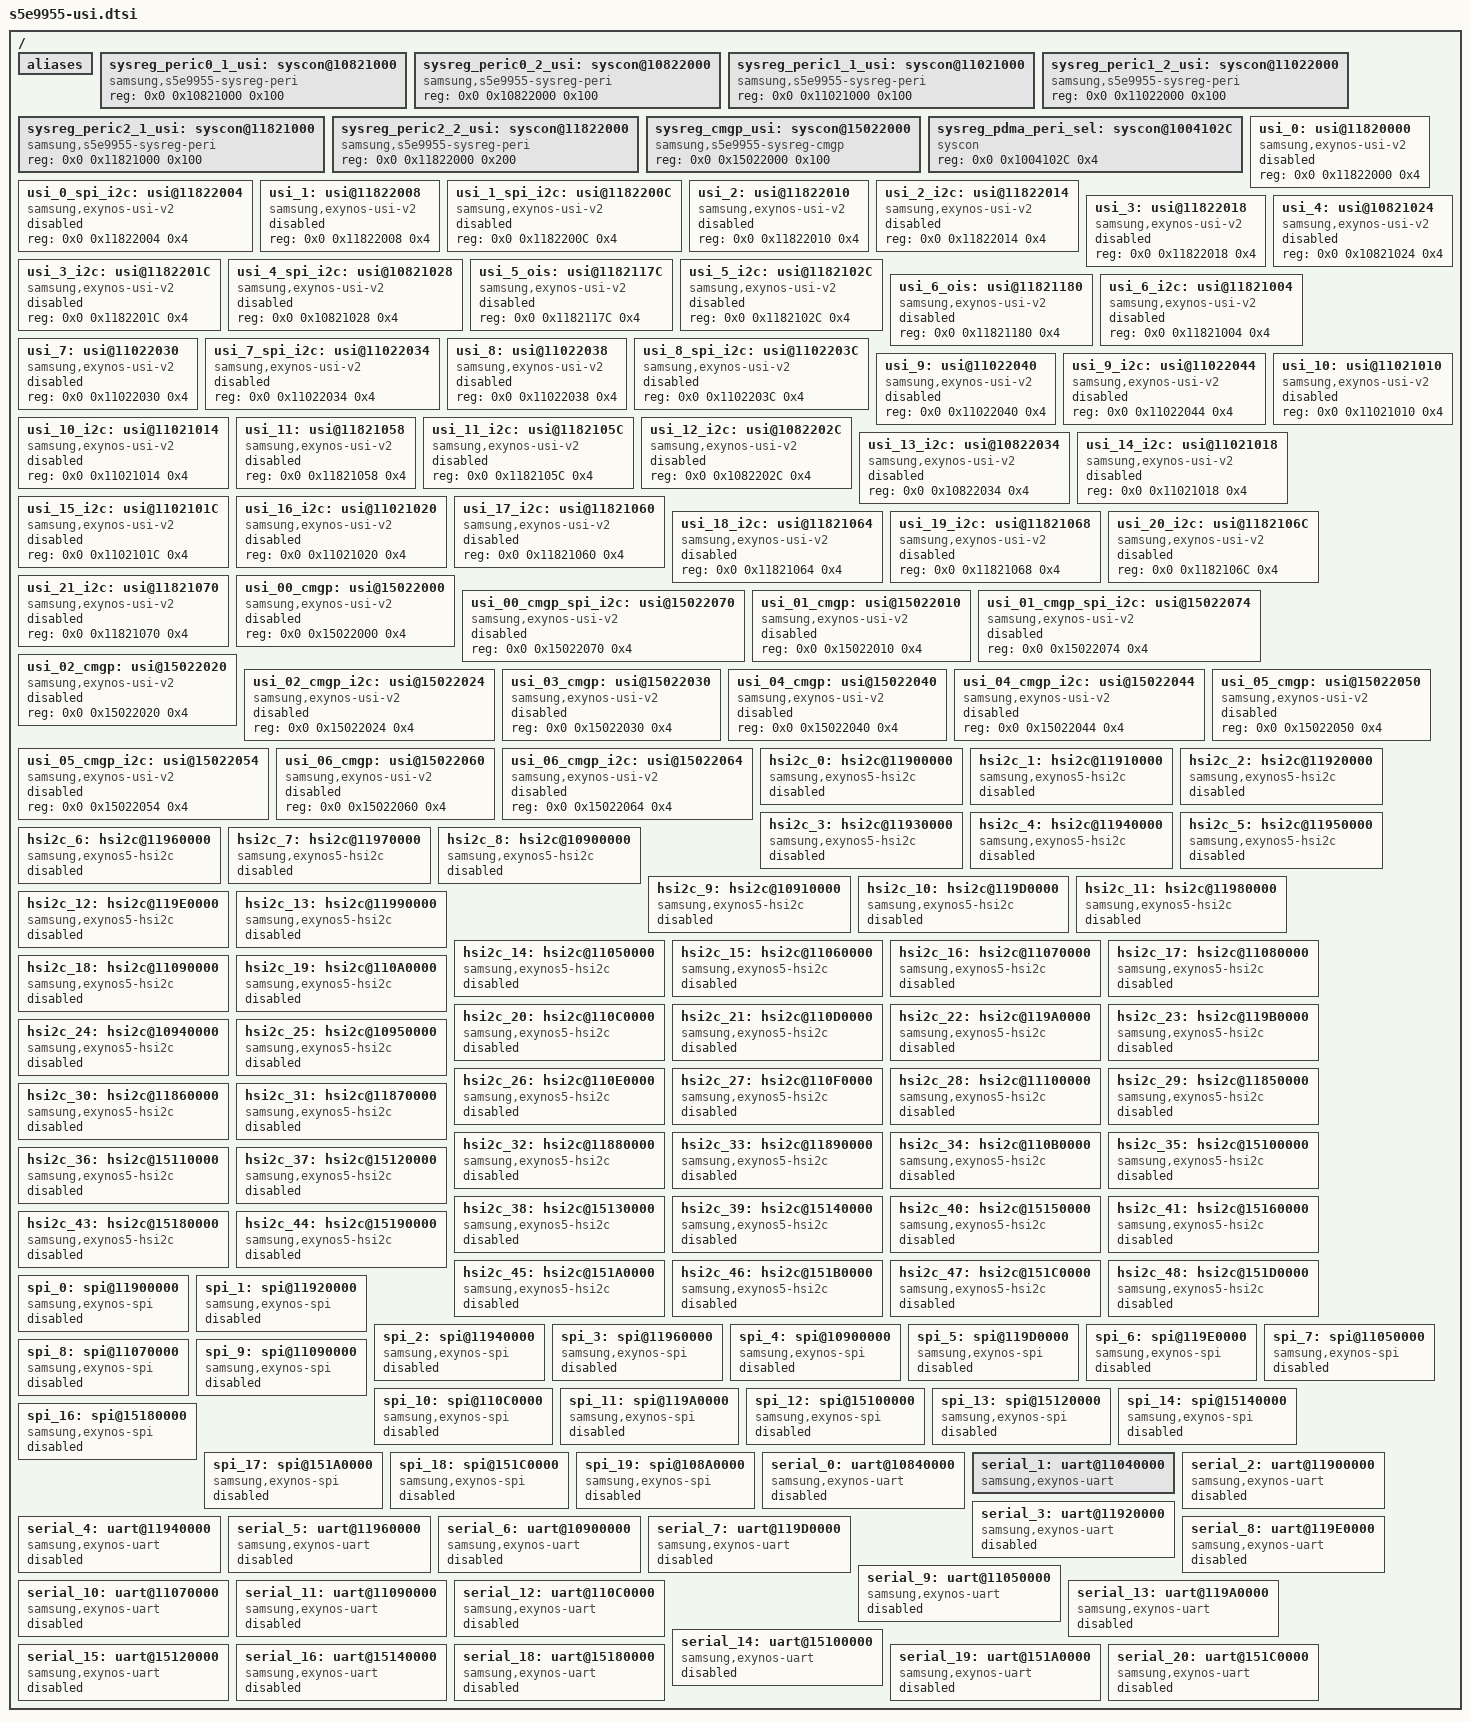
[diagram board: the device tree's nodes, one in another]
/*
 * Samsung's s5e9955 SoC USI device tree source
 *
 * Copyright (c) 2023 Samsung Electronics Co., Ltd.
 *		http://www.samsung.com
 *
 * Samsung's s5e9955 SoC USI channels are listed as device
 * tree nodes are listed in this file.
 *
 * This program is free software; you can redistribute it and/or modify
 * it under the terms of the GNU General Public License version 2 as
 * published by the Free Software Foundation.
*/

/ {
	aliases {
		usi00 = &usi_0;
		usi01 = &usi_0_spi_i2c;
		usi02 = &usi_1;
		usi03 = &usi_1_spi_i2c;
		usi04 = &usi_2;
		usi05 = &usi_2_i2c;
		usi06 = &usi_3;
		usi07 = &usi_3_i2c;
		usi08 = &usi_4;
		usi09 = &usi_4_spi_i2c;
		usi10 = &usi_5_ois;
		usi11 = &usi_5_i2c;
		usi12 = &usi_6_ois;
		usi13 = &usi_6_i2c;
		usi14 = &usi_7;
		usi15 = &usi_7_spi_i2c;
		usi16 = &usi_8;
		usi17 = &usi_8_spi_i2c;
		usi18 = &usi_9;
		usi19 = &usi_9_i2c;
		usi20 = &usi_10;
		usi21 = &usi_10_i2c;
		usi22 = &usi_11;
		usi23 = &usi_11_i2c;
		usi24 = &usi_12_i2c;
		usi25 = &usi_13_i2c;
		usi26 = &usi_14_i2c;
		usi27 = &usi_15_i2c;
		usi28 = &usi_16_i2c;
		usi29 = &usi_17_i2c;
		usi30 = &usi_18_i2c;
		usi31 = &usi_19_i2c;
		usi32 = &usi_20_i2c;
		usi33 = &usi_21_i2c;
		usi34 = &usi_00_cmgp;
		usi35 = &usi_00_cmgp_spi_i2c;
		usi36 = &usi_01_cmgp;
		usi37 = &usi_01_cmgp_spi_i2c;
		usi38 = &usi_02_cmgp;
		usi39 = &usi_02_cmgp_i2c;
		usi40 = &usi_03_cmgp;
		//usi41 = &usi_03_cmgp_i2c;
		usi42 = &usi_04_cmgp;
		usi43 = &usi_04_cmgp_i2c;
		usi44 = &usi_05_cmgp;
		usi45 = &usi_05_cmgp_i2c;
		usi46 = &usi_06_cmgp;
		usi47 = &usi_06_cmgp_i2c;
		i2c0 = &hsi2c_0;
		i2c1 = &hsi2c_1;
		i2c2 = &hsi2c_2;
		i2c3 = &hsi2c_3;
		i2c4 = &hsi2c_4;
		i2c5 = &hsi2c_5;
		i2c6 = &hsi2c_6;
		i2c7 = &hsi2c_7;
		i2c8 = &hsi2c_8;
		i2c9 = &hsi2c_9;
		i2c10 = &hsi2c_10;
		i2c11 = &hsi2c_11;
		i2c12 = &hsi2c_12;
		i2c13 = &hsi2c_13;
		i2c14 = &hsi2c_14;
		i2c15 = &hsi2c_15;
		i2c16 = &hsi2c_16;
		i2c17 = &hsi2c_17;
		i2c18 = &hsi2c_18;
		i2c19 = &hsi2c_19;
		i2c20 = &hsi2c_20;
		i2c21 = &hsi2c_21;
		i2c22 = &hsi2c_22;
		i2c23 = &hsi2c_23;
		i2c24 = &hsi2c_24;
		i2c25 = &hsi2c_25;
		i2c26 = &hsi2c_26;
		i2c27 = &hsi2c_27;
		i2c28 = &hsi2c_28;
		i2c29 = &hsi2c_29;
		i2c30 = &hsi2c_30;
		i2c31 = &hsi2c_31;
		i2c32 = &hsi2c_32;
		i2c33 = &hsi2c_33;
		i2c34 = &hsi2c_34;
		i2c35 = &hsi2c_35;
		i2c36 = &hsi2c_36;
		i2c37 = &hsi2c_37;
		i2c38 = &hsi2c_38;
		i2c39 = &hsi2c_39;
		i2c40 = &hsi2c_40;
		i2c41 = &hsi2c_41;
		//hsi2c42 = &hsi2c_42;
		i2c43 = &hsi2c_43;
		i2c44 = &hsi2c_44;
		i2c45 = &hsi2c_45;
		i2c46 = &hsi2c_46;
		i2c47 = &hsi2c_47;
		i2c48 = &hsi2c_48;

		// Exynos SoC mfd
		i2c50 = &esca_mfd_bus0;
		i2c51 = &esca_mfd_bus1;
		i2c52 = &esca_mfd_bus2;
		i2c53 = &esca_mfd_bus3;
		i2c54 = &esca_mfd_bus4;
		i2c55 = &esca_mfd_bus5;
		i2c56 = &esca_mfd_bus6;
		i2c57 = &esca_mfd_bus7;
		i2c58 = &esca_mfd_bus8;

		spi0 = &spi_0;
		spi1 = &spi_1;
		spi2 = &spi_2;
		spi3 = &spi_3;
		spi4 = &spi_4;
		spi5 = &spi_5;
		spi6 = &spi_6;
		spi7 = &spi_7;
		spi8 = &spi_8;
		spi9 = &spi_9;
		spi10 = &spi_10;
		spi11 = &spi_11;
		spi12 = &spi_12;
		spi13 = &spi_13;
		spi14 = &spi_14;
		//spi15 = &spi_15;
		spi16 = &spi_16;
		spi17 = &spi_17;
		spi18 = &spi_18;
		spi19 = &spi_19;
		uart0 = &serial_0;
		uart1 = &serial_1;
		uart2 = &serial_2;
		uart3 = &serial_3;
		uart4 = &serial_4;
		uart5 = &serial_5;
		uart6 = &serial_6;
		uart7 = &serial_7;
		uart8 = &serial_8;
		uart9 = &serial_9;
		uart10 = &serial_10;
		uart11 = &serial_11;
		uart12 = &serial_12;
		uart13 = &serial_13;
		uart14 = &serial_14;
		uart15 = &serial_15;
		uart16 = &serial_16;
		//uart17 = &serial_17;
		uart18 = &serial_18;
		uart19 = &serial_19;
		uart20 = &serial_20;
	};

	/* USI_SW_CONF for PERIC0-1 USI*/
	sysreg_peric0_1_usi: syscon@10821000 {
		compatible = "samsung,s5e9955-sysreg-peri", "syscon";
		reg = <0x0 0x10821000 0x100>;
	};

	/* USI_SW_CONF for PERIC0-2 USI*/
	sysreg_peric0_2_usi: syscon@10822000 {
		compatible = "samsung,s5e9955-sysreg-peri", "syscon";
		reg = <0x0 0x10822000 0x100>;
	};

	/* USI_SW_CONF for PERIC1-1 USI*/
	sysreg_peric1_1_usi: syscon@11021000 {
		compatible = "samsung,s5e9955-sysreg-peri", "syscon";
		reg = <0x0 0x11021000 0x100>;
	};

	/* USI_SW_CONF for PERIC1-2 USI*/
	sysreg_peric1_2_usi: syscon@11022000 {
		compatible = "samsung,s5e9955-sysreg-peri", "syscon";
		reg = <0x0 0x11022000 0x100>;
	};

	/* USI_SW_CONF for PERIC2-1 USI*/
	sysreg_peric2_1_usi: syscon@11821000 {
		compatible = "samsung,s5e9955-sysreg-peri", "syscon";
		reg = <0x0 0x11821000 0x100>;
	};

	/* USI_SW_CONF for PERIC2-2 USI*/
	sysreg_peric2_2_usi: syscon@11822000 {
		compatible = "samsung,s5e9955-sysreg-peri", "syscon";
		reg = <0x0 0x11822000 0x200>;
	};

	/* USI_SW_CONF for CMGP USI*/
	sysreg_cmgp_usi: syscon@15022000 {
		compatible = "samsung,s5e9955-sysreg-cmgp", "syscon";
		reg = <0x0 0x15022000 0x100>;
	};

	/* SYSREG PDMA_PERI_SEL */
	/* Refer to UM System register PDMA_PERI_SEL */
	sysreg_pdma_peri_sel: syscon@1004102C {
		compatible = "syscon";
		reg = <0x0 0x1004102C 0x4>;
	};

	/* USI_0 */
	usi_0: usi@11820000 {
		compatible = "samsung,exynos-usi-v2";
		reg = <0x0 0x11822000 0x4>;
		/*	usi_v2_mode = "i2c" or "spi" or "uart"	*/
		status = "disabled";
	};

	/* USI_0_SPI_I2C */
	usi_0_spi_i2c: usi@11822004 {
		compatible = "samsung,exynos-usi-v2";
		reg = <0x0 0x11822004 0x4>;
		/*	usi_v2_mode = "i2c" or "spi" or "uart"	*/
		status = "disabled";
	};

	/* USI_1 */
	usi_1: usi@11822008 {
		compatible = "samsung,exynos-usi-v2";
		reg = <0x0 0x11822008 0x4>;
		/*	usi_v2_mode = "i2c" or "spi" or "uart"	*/
		status = "disabled";
	};

	/* USI_1_SPI_I2C */
	usi_1_spi_i2c: usi@1182200C {
		compatible = "samsung,exynos-usi-v2";
		reg = <0x0 0x1182200C 0x4>;
		/*	usi_v2_mode = "i2c" or "spi" or "uart"	*/
		status = "disabled";
	};

	/* USI_2 */
	usi_2: usi@11822010 {
		compatible = "samsung,exynos-usi-v2";
		reg = <0x0 0x11822010 0x4>;
		/*	usi_v2_mode = "i2c" or "spi" or "uart"	*/
		status = "disabled";
	};

	/* USI_2_I2C */
	usi_2_i2c: usi@11822014 {
		compatible = "samsung,exynos-usi-v2";
		reg = <0x0 0x11822014 0x4>;
		/*	usi_v2_mode = "i2c" or "spi" or "uart"	*/
		status = "disabled";
	};

	/* USI_3 */
	usi_3: usi@11822018 {
		compatible = "samsung,exynos-usi-v2";
		reg = <0x0 0x11822018 0x4>;
		/*	usi_v2_mode = "i2c" or "spi" or "uart"	*/
		status = "disabled";
	};

	/* USI_3_I2C */
	usi_3_i2c: usi@1182201C {
		compatible = "samsung,exynos-usi-v2";
		reg = <0x0 0x1182201C 0x4>;
		/*	usi_v2_mode = "i2c" or "spi" or "uart"	*/
		status = "disabled";
	};

	/* USI_4 */
	usi_4: usi@10821024 {
		compatible = "samsung,exynos-usi-v2";
		reg = <0x0 0x10821024 0x4>;
		/*	usi_v2_mode = "i2c" or "spi" or "uart"	*/
		status = "disabled";
	};

	/* USI_4_I2C */
	usi_4_spi_i2c: usi@10821028 {
		compatible = "samsung,exynos-usi-v2";
		reg = <0x0 0x10821028 0x4>;
		/*	usi_v2_mode = "i2c" or "spi" or "uart"	*/
		status = "disabled";
	};

	/* USI_5_OIS */
	usi_5_ois: usi@1182117C {
		compatible = "samsung,exynos-usi-v2";
		reg = <0x0 0x1182117C 0x4>;
		/*	usi_v2_mode = "i2c" or "spi" or "uart"	*/
		status = "disabled";
	};

	/* USI_5_I2C */
	usi_5_i2c: usi@1182102C {
		compatible = "samsung,exynos-usi-v2";
		reg = <0x0 0x1182102C 0x4>;
		/*	usi_v2_mode = "i2c" or "spi" or "uart"	*/
		status = "disabled";
	};

	/* USI_6_OIS */
	usi_6_ois: usi@11821180 {
		compatible = "samsung,exynos-usi-v2";
		reg = <0x0 0x11821180 0x4>;
		/*	usi_v2_mode = "i2c" or "spi" or "uart"	*/
		status = "disabled";
	};

	/* USI_6_I2C */
	usi_6_i2c: usi@11821004 {
		compatible = "samsung,exynos-usi-v2";
		reg = <0x0 0x11821004 0x4>;
		/*	usi_v2_mode = "i2c" or "spi" or "uart"	*/
		status = "disabled";
	};

	/* USI_7 */
	usi_7: usi@11022030 {
		compatible = "samsung,exynos-usi-v2";
		reg = <0x0 0x11022030 0x4>;
		/*	usi_v2_mode = "i2c" or "spi" or "uart"	*/
		status = "disabled";
	};

	/* USI_7_SPI_I2C */
	usi_7_spi_i2c: usi@11022034 {
		compatible = "samsung,exynos-usi-v2";
		reg = <0x0 0x11022034 0x4>;
		/*	usi_v2_mode = "i2c" or "spi" or "uart"	*/
		status = "disabled";
	};

	/* USI_8 */
	usi_8: usi@11022038 {
		compatible = "samsung,exynos-usi-v2";
		reg = <0x0 0x11022038 0x4>;
		/*	usi_v2_mode = "i2c" or "spi" or "uart"	*/
		status = "disabled";
	};

	/* USI_8_SPI_I2C */
	usi_8_spi_i2c: usi@1102203C {
		compatible = "samsung,exynos-usi-v2";
		reg = <0x0 0x1102203C 0x4>;
		/*	usi_v2_mode = "i2c" or "spi" or "uart"	*/
		status = "disabled";
	};

	/* USI_9 */
	usi_9: usi@11022040 {
		compatible = "samsung,exynos-usi-v2";
		reg = <0x0 0x11022040 0x4>;
		/*	usi_v2_mode = "i2c" or "spi" or "uart"	*/
		status = "disabled";
	};

	/* USI_9_I2C */
	usi_9_i2c: usi@11022044 {
		compatible = "samsung,exynos-usi-v2";
		reg = <0x0 0x11022044 0x4>;
		/*	usi_v2_mode = "i2c" or "spi" or "uart"	*/
		status = "disabled";
	};

	/* USI_10 */
	usi_10: usi@11021010 {
		compatible = "samsung,exynos-usi-v2";
		reg = <0x0 0x11021010 0x4>;
		/*	usi_v2_mode = "i2c" or "spi" or "uart"	*/
		status = "disabled";
	};

	/* USI_10_I2C */
	usi_10_i2c: usi@11021014 {
		compatible = "samsung,exynos-usi-v2";
		reg = <0x0 0x11021014 0x4>;
		/*	usi_v2_mode = "i2c" or "spi" or "uart"	*/
		status = "disabled";
	};

	/* USI_11 */
	usi_11: usi@11821058 {
		compatible = "samsung,exynos-usi-v2";
		reg = <0x0 0x11821058 0x4>;
		/*	usi_v2_mode = "i2c" or "spi" or "uart"	*/
		status = "disabled";
	};

	/* USI_11_I2C */
	usi_11_i2c: usi@1182105C {
		compatible = "samsung,exynos-usi-v2";
		reg = <0x0 0x1182105C 0x4>;
		/*	usi_v2_mode = "i2c" or "spi" or "uart"	*/
		status = "disabled";
	};

	/* USI_12_I2C */
	usi_12_i2c: usi@1082202C {
		compatible = "samsung,exynos-usi-v2";
		reg = <0x0 0x1082202C 0x4>;
		/*	usi_v2_mode = "i2c" or "spi" or "uart"	*/
		status = "disabled";
	};

	/* USI_13_I2C */
	usi_13_i2c: usi@10822034 {
		compatible = "samsung,exynos-usi-v2";
		reg = <0x0 0x10822034 0x4>;
		/*	usi_v2_mode = "i2c" or "spi" or "uart"	*/
		status = "disabled";
	};

	/* USI_14_I2C */
	usi_14_i2c: usi@11021018 {
		compatible = "samsung,exynos-usi-v2";
		reg = <0x0 0x11021018 0x4>;
		/*	usi_v2_mode = "i2c" or "spi" or "uart"	*/
		status = "disabled";
	};

	/* USI_15_I2C */
	usi_15_i2c: usi@1102101C {
		compatible = "samsung,exynos-usi-v2";
		reg = <0x0 0x1102101C 0x4>;
		/*	usi_v2_mode = "i2c" or "spi" or "uart"	*/
		status = "disabled";
	};

	/* USI_16_I2C */
	usi_16_i2c: usi@11021020 {
		compatible = "samsung,exynos-usi-v2";
		reg = <0x0 0x11021020 0x4>;
		/*	usi_v2_mode = "i2c" or "spi" or "uart"	*/
		status = "disabled";
	};

	/* USI_17_I2C */
	usi_17_i2c: usi@11821060 {
		compatible = "samsung,exynos-usi-v2";
		reg = <0x0 0x11821060 0x4>;
		/*	usi_v2_mode = "i2c" or "spi" or "uart"	*/
		status = "disabled";
	};

	/* USI_18_I2C */
	usi_18_i2c: usi@11821064 {
		compatible = "samsung,exynos-usi-v2";
		reg = <0x0 0x11821064 0x4>;
		/*	usi_v2_mode = "i2c" or "spi" or "uart"	*/
		status = "disabled";
	};

	/* USI_19_I2C */
	usi_19_i2c: usi@11821068 {
		compatible = "samsung,exynos-usi-v2";
		reg = <0x0 0x11821068 0x4>;
		/*	usi_v2_mode = "i2c" or "spi" or "uart"	*/
		status = "disabled";
	};

	/* USI_20_I2C */
	usi_20_i2c: usi@1182106C {
		compatible = "samsung,exynos-usi-v2";
		reg = <0x0 0x1182106C 0x4>;
		/*	usi_v2_mode = "i2c" or "spi" or "uart"	*/
		status = "disabled";
	};

	/* USI_21_I2C */
	usi_21_i2c: usi@11821070 {
		compatible = "samsung,exynos-usi-v2";
		reg = <0x0 0x11821070 0x4>;
		/*	usi_v2_mode = "i2c" or "spi" or "uart"	*/
		status = "disabled";
	};

	/* USI_CMGP0_USI */
	usi_00_cmgp: usi@15022000 {
		compatible = "samsung,exynos-usi-v2";
		reg = <0x0 0x15022000 0x4>;
		/*	usi_v2_mode = "i2c" or "spi" or "uart"	*/
		status = "disabled";
	};

	/* USI_CMGP0_SPI_I2C */
	usi_00_cmgp_spi_i2c: usi@15022070 {
		compatible = "samsung,exynos-usi-v2";
		reg = <0x0 0x15022070 0x4>;
		/*	usi_v2_mode = "i2c" or "spi" or "uart"	*/
		status = "disabled";
	};

	/* USI_CMGP1_USI */
	usi_01_cmgp: usi@15022010 {
		compatible = "samsung,exynos-usi-v2";
		reg = <0x0 0x15022010 0x4>;
		/*	usi_v2_mode = "i2c" or "spi" or "uart"	*/
		status = "disabled";
	};

	/* USI_CMGP1_SPI_I2C */
	usi_01_cmgp_spi_i2c: usi@15022074 {
		compatible = "samsung,exynos-usi-v2";
		reg = <0x0 0x15022074 0x4>;
		/*	usi_v2_mode = "i2c" or "spi" or "uart"	*/
		status = "disabled";
	};

	/* USI_CMGP2_USI */
	usi_02_cmgp: usi@15022020 {
		compatible = "samsung,exynos-usi-v2";
		reg = <0x0 0x15022020 0x4>;
		/*	usi_v2_mode = "i2c" or "spi" or "uart"	*/
		status = "disabled";
	};

	/* USI_CMGP2_I2C */
	usi_02_cmgp_i2c: usi@15022024 {
		compatible = "samsung,exynos-usi-v2";
		reg = <0x0 0x15022024 0x4>;
		/*	usi_v2_mode = "i2c" or "spi" or "uart"	*/
		status = "disabled";
	};

	/* USI_CMGP3_USI */
	usi_03_cmgp: usi@15022030 {
		compatible = "samsung,exynos-usi-v2";
		reg = <0x0 0x15022030 0x4>;
		/*	usi_v2_mode = "i2c" or "spi" or "uart"	*/
		status = "disabled";
	};

	/* USI_CMGP3_I2C */
/*
	usi_03_cmgp_i2c: usi@15022034 {
		compatible = "samsung,exynos-usi-v2";
		reg = <0x0 0x15022034 0x4>;
		//	usi_v2_mode = "i2c" or "spi" or "uart"
		status = "disabled";
	};
*/
	/* USI_CMGP4_USI */
	usi_04_cmgp: usi@15022040 {
		compatible = "samsung,exynos-usi-v2";
		reg = <0x0 0x15022040 0x4>;
		/*	usi_v2_mode = "i2c" or "spi" or "uart"	*/
		status = "disabled";
	};

	/* USI_CMGP4_I2C */
	usi_04_cmgp_i2c: usi@15022044 {
		compatible = "samsung,exynos-usi-v2";
		reg = <0x0 0x15022044 0x4>;
		/*	usi_v2_mode = "i2c" or "spi" or "uart"	*/
		status = "disabled";
	};

	/* USI_CMGP5_USI */
	usi_05_cmgp: usi@15022050 {
		compatible = "samsung,exynos-usi-v2";
		reg = <0x0 0x15022050 0x4>;
		/*	usi_v2_mode = "i2c" or "spi" or "uart"	*/
		status = "disabled";
	};

	/* USI_CMGP5_I2C */
	usi_05_cmgp_i2c: usi@15022054 {
		compatible = "samsung,exynos-usi-v2";
		reg = <0x0 0x15022054 0x4>;
		/*	usi_v2_mode = "i2c" or "spi" or "uart"	*/
		status = "disabled";
	};

	/* USI_CMGP6_USI */
	usi_06_cmgp: usi@15022060 {
		compatible = "samsung,exynos-usi-v2";
		reg = <0x0 0x15022060 0x4>;
		/*	usi_v2_mode = "i2c" or "spi" or "uart"	*/
		status = "disabled";
	};

	/* USI_CMGP6_I2C */
	usi_06_cmgp_i2c: usi@15022064 {
		compatible = "samsung,exynos-usi-v2";
		reg = <0x0 0x15022064 0x4>;
		/*	usi_v2_mode = "i2c" or "spi" or "uart"	*/
		status = "disabled";
	};

	/* USI00_USI */
	hsi2c_0: hsi2c@11900000 {
		compatible = "samsung,exynos5-hsi2c";
		samsung,check-transdone-int;
		default-clk = <200000000>;
		samsung,scl-clk-stretching;
		samsung,reset-before-trans;
		samsung,i2c-bus-clear = <1>;
		#address-cells = <1>;
		#size-cells = <0>;
		interrupts = <GIC_SPI INTREQ__USI00_USI IRQ_TYPE_LEVEL_HIGH>;
		samsung,usi-phandle = <&sysreg_peric2_2_usi>;
		samsung,usi-offset = <0x00>;
		reg = <0x0 0x11900000 0x1000>;
		pinctrl-names = "default", "bus_io";
		pinctrl-0 = <&hsi2c0_bus>;
		pinctrl-1 = <&hsi2c0_bus_io>;
		clocks = <&clock DOUT_DIV_CLK_PERIC2_USI00>, <&clock GATE_PERIC2_CMU_PERIC2_QCH>;
		clock-names = "ipclk_hsi2c", "gate_hsi2c_clk";
		gpio_scl= <&gpp0 0 0x1>;
		gpio_sda= <&gpp0 1 0x1>;
		status = "disabled";
	};

	/* USI00_I2C */
	hsi2c_1: hsi2c@11910000 {
		compatible = "samsung,exynos5-hsi2c";
		samsung,check-transdone-int;
		default-clk = <200000000>;
		samsung,scl-clk-stretching;
		samsung,reset-before-trans;
		samsung,i2c-bus-clear = <1>;
		#address-cells = <1>;
		#size-cells = <0>;
		interrupts = <GIC_SPI INTREQ__USI00_SPI_I2C IRQ_TYPE_LEVEL_HIGH>;
		samsung,usi-phandle = <&sysreg_peric2_2_usi>;
		samsung,usi-offset = <0x04>;
		reg = <0x0 0x11910000 0x1000>;
		pinctrl-names = "default", "bus_io";
		pinctrl-0 = <&hsi2c1_bus>;
		pinctrl-1 = <&hsi2c1_bus_io>;
		clocks = <&clock DOUT_DIV_CLK_PERIC2_USI00_SPI_I2C>, <&clock GATE_PERIC2_CMU_PERIC2_QCH>;
		clock-names = "ipclk_hsi2c", "gate_hsi2c_clk";
		gpio_scl= <&gpp0 2 0x1>;
		gpio_sda= <&gpp0 3 0x1>;
		status = "disabled";
	};

	/* USI01_USI */
	hsi2c_2: hsi2c@11920000 {
		compatible = "samsung,exynos5-hsi2c";
		samsung,check-transdone-int;
		default-clk = <200000000>;
		samsung,scl-clk-stretching;
		samsung,reset-before-trans;
		samsung,i2c-bus-clear = <1>;
		#address-cells = <1>;
		#size-cells = <0>;
		interrupts = <GIC_SPI INTREQ__USI01_USI IRQ_TYPE_LEVEL_HIGH>;
		samsung,usi-phandle = <&sysreg_peric2_2_usi>;
		samsung,usi-offset = <0x08>;
		reg = <0x0 0x11920000 0x1000>;
		pinctrl-names = "default", "bus_io";
		pinctrl-0 = <&hsi2c2_bus>;
		pinctrl-1 = <&hsi2c2_bus_io>;
		clocks = <&clock DOUT_DIV_CLK_PERIC2_USI01>, <&clock GATE_PERIC2_CMU_PERIC2_QCH>;
		clock-names = "ipclk_hsi2c", "gate_hsi2c_clk";
		gpio_scl= <&gpp1 0 0x1>;
		gpio_sda= <&gpp1 1 0x1>;
		status = "disabled";
	};

	/* USI01_I2C */
	hsi2c_3: hsi2c@11930000 {
		compatible = "samsung,exynos5-hsi2c";
		samsung,check-transdone-int;
		default-clk = <200000000>;
		samsung,scl-clk-stretching;
		samsung,reset-before-trans;
		samsung,i2c-bus-clear = <1>;
		#address-cells = <1>;
		#size-cells = <0>;
		interrupts = <GIC_SPI INTREQ__USI01_SPI_I2C IRQ_TYPE_LEVEL_HIGH>;
		samsung,usi-phandle = <&sysreg_peric2_2_usi>;
		samsung,usi-offset = <0x0C>;
		reg = <0x0 0x11930000 0x1000>;
		pinctrl-names = "default", "bus_io";
		pinctrl-0 = <&hsi2c3_bus>;
		pinctrl-1 = <&hsi2c3_bus_io>;
		clocks = <&clock DOUT_DIV_CLK_PERIC2_USI01_SPI_I2C>, <&clock GATE_PERIC2_CMU_PERIC2_QCH>;
		clock-names = "ipclk_hsi2c", "gate_hsi2c_clk";
		gpio_scl= <&gpp1 2 0x1>;
		gpio_sda= <&gpp1 3 0x1>;
		status = "disabled";
	};

	/* USI02_USI */
	hsi2c_4: hsi2c@11940000 {
		compatible = "samsung,exynos5-hsi2c";
		samsung,check-transdone-int;
		default-clk = <200000000>;
		samsung,scl-clk-stretching;
		samsung,reset-before-trans;
		samsung,i2c-bus-clear = <1>;
		#address-cells = <1>;
		#size-cells = <0>;
		interrupts = <GIC_SPI INTREQ__USI02_USI IRQ_TYPE_LEVEL_HIGH>;
		samsung,usi-phandle = <&sysreg_peric2_2_usi>;
		samsung,usi-offset = <0x10>;
		reg = <0x0 0x11940000 0x1000>;
		pinctrl-names = "default", "bus_io";
		pinctrl-0 = <&hsi2c4_bus>;
		pinctrl-1 = <&hsi2c4_bus_io>;
		clocks = <&clock DOUT_DIV_CLK_PERIC2_USI02>, <&clock GATE_PERIC2_CMU_PERIC2_QCH>;
		clock-names = "ipclk_hsi2c", "gate_hsi2c_clk";
		gpio_scl= <&gpp2 0 0x1>;
		gpio_sda= <&gpp2 1 0x1>;
		status = "disabled";
	};

	/* USI02_I2C */
	hsi2c_5: hsi2c@11950000 {
		compatible = "samsung,exynos5-hsi2c";
		samsung,check-transdone-int;
		default-clk = <200000000>;
		samsung,scl-clk-stretching;
		samsung,reset-before-trans;
		samsung,i2c-bus-clear = <1>;
		#address-cells = <1>;
		#size-cells = <0>;
		interrupts = <GIC_SPI INTREQ__USI02_I2C IRQ_TYPE_LEVEL_HIGH>;
		samsung,usi-phandle = <&sysreg_peric2_2_usi>;
		samsung,usi-offset = <0x14>;
		reg = <0x0 0x11950000 0x1000>;
		pinctrl-names = "default", "bus_io";
		pinctrl-0 = <&hsi2c5_bus>;
		pinctrl-1 = <&hsi2c5_bus_io>;
		clocks = <&clock DOUT_DIV_CLK_PERIC2_I2C>, <&clock GATE_PERIC2_CMU_PERIC2_QCH>;
		clock-names = "ipclk_hsi2c", "gate_hsi2c_clk";
		gpio_scl= <&gpp2 2 0x1>;
		gpio_sda= <&gpp2 3 0x1>;
		status = "disabled";
	};

	/* USI03_USI */
	hsi2c_6: hsi2c@11960000 {
		compatible = "samsung,exynos5-hsi2c";
		samsung,check-transdone-int;
		default-clk = <200000000>;
		samsung,scl-clk-stretching;
		samsung,reset-before-trans;
		samsung,i2c-bus-clear = <1>;
		#address-cells = <1>;
		#size-cells = <0>;
		interrupts = <GIC_SPI INTREQ__USI03_USI IRQ_TYPE_LEVEL_HIGH>;
		samsung,usi-phandle = <&sysreg_peric2_2_usi>;
		samsung,usi-offset = <0x18>;
		reg = <0x0 0x11960000 0x1000>;
		pinctrl-names = "default", "bus_io";
		pinctrl-0 = <&hsi2c6_bus>;
		pinctrl-1 = <&hsi2c6_bus_io>;
		clocks = <&clock DOUT_DIV_CLK_PERIC2_USI03>, <&clock GATE_PERIC2_CMU_PERIC2_QCH>;
		clock-names = "ipclk_hsi2c", "gate_hsi2c_clk";
		gpio_scl= <&gpp3 0 0x1>;
		gpio_sda= <&gpp3 1 0x1>;
		status = "disabled";
	};

	/* USI03_I2C */
	hsi2c_7: hsi2c@11970000 {
		compatible = "samsung,exynos5-hsi2c";
		samsung,check-transdone-int;
		default-clk = <200000000>;
		samsung,scl-clk-stretching;
		samsung,reset-before-trans;
		samsung,i2c-bus-clear = <1>;
		#address-cells = <1>;
		#size-cells = <0>;
		interrupts = <GIC_SPI INTREQ__USI03_I2C IRQ_TYPE_LEVEL_HIGH>;
		samsung,usi-phandle = <&sysreg_peric2_2_usi>;
		samsung,usi-offset = <0x1C>;
		reg = <0x0 0x11970000 0x1000>;
		pinctrl-names = "default", "bus_io";
		pinctrl-0 = <&hsi2c7_bus>;
		pinctrl-1 = <&hsi2c7_bus_io>;
		clocks = <&clock DOUT_DIV_CLK_PERIC2_I2C>, <&clock GATE_PERIC2_CMU_PERIC2_QCH>;
		clock-names = "ipclk_hsi2c", "gate_hsi2c_clk";
		gpio_scl= <&gpp3 2 0x1>;
		gpio_sda= <&gpp3 3 0x1>;
		status = "disabled";
	};

	/* USI04_USI */
	hsi2c_8: hsi2c@10900000 {
		compatible = "samsung,exynos5-hsi2c";
		samsung,check-transdone-int;
		default-clk = <200000000>;
		samsung,scl-clk-stretching;
		samsung,reset-before-trans;
		samsung,i2c-bus-clear = <1>;
		#address-cells = <1>;
		#size-cells = <0>;
		interrupts = <GIC_SPI INTREQ__USI04_USI IRQ_TYPE_LEVEL_HIGH>;
		samsung,usi-phandle = <&sysreg_peric0_1_usi>;
		samsung,usi-offset = <0x24>;
		reg = <0x0 0x10900000 0x1000>;
		pinctrl-names = "default", "bus_io";
		pinctrl-0 = <&hsi2c8_bus>;
		pinctrl-1 = <&hsi2c8_bus_io>;
		clocks = <&clock DOUT_DIV_CLK_PERIC0_USI04>, <&clock GATE_PERIC0_CMU_PERIC0_QCH>;
		clock-names = "ipclk_hsi2c", "gate_hsi2c_clk";
		gpio_scl= <&gpp4 0 0x1>;
		gpio_sda= <&gpp4 1 0x1>;
		status = "disabled";
	};

	/* USI04_I2C */
	hsi2c_9: hsi2c@10910000 {
		compatible = "samsung,exynos5-hsi2c";
		samsung,check-transdone-int;
		default-clk = <200000000>;
		samsung,scl-clk-stretching;
		samsung,reset-before-trans;
		samsung,i2c-bus-clear = <1>;
		#address-cells = <1>;
		#size-cells = <0>;
		interrupts = <GIC_SPI INTREQ__USI04_I2C IRQ_TYPE_LEVEL_HIGH>;
		samsung,usi-phandle = <&sysreg_peric0_1_usi>;
		samsung,usi-offset = <0x28>;
		reg = <0x0 0x10910000 0x1000>;
		pinctrl-names = "default", "bus_io";
		pinctrl-0 = <&hsi2c9_bus>;
		pinctrl-1 = <&hsi2c9_bus_io>;
		clocks = <&clock DOUT_DIV_CLK_PERIC0_I2C>, <&clock GATE_PERIC0_CMU_PERIC0_QCH>;
		clock-names = "ipclk_hsi2c", "gate_hsi2c_clk";
		gpio_scl= <&gpp4 2 0x1>;
		gpio_sda= <&gpp4 3 0x1>;
		status = "disabled";
	};

	/* USI05_USI_OIS */
	hsi2c_10: hsi2c@119D0000 {
		compatible = "samsung,exynos5-hsi2c";
		samsung,check-transdone-int;
		default-clk = <200000000>;
		samsung,scl-clk-stretching;
		samsung,reset-before-trans;
		samsung,i2c-bus-clear = <1>;
		#address-cells = <1>;
		#size-cells = <0>;
		interrupts = <GIC_SPI INTREQ__USI05_USI_OIS IRQ_TYPE_LEVEL_HIGH>;
		samsung,usi-phandle = <&sysreg_peric2_1_usi>;
		samsung,usi-offset = <0x17C>;
		reg = <0x0 0x119D0000 0x1000>;
		pinctrl-names = "default", "bus_io";
		pinctrl-0 = <&hsi2c10_bus>;
		pinctrl-1 = <&hsi2c10_bus_io>;
		clocks = <&clock DOUT_DIV_CLK_PERIC2_USI05>, <&clock GATE_PERIC2_CMU_PERIC2_QCH>;
		clock-names = "ipclk_hsi2c", "gate_hsi2c_clk";
		gpio_scl= <&gpp5 0 0x1>;
		gpio_sda= <&gpp5 1 0x1>;
		status = "disabled";
	};

	/* USI05_I2C */
	hsi2c_11: hsi2c@11980000 {
		compatible = "samsung,exynos5-hsi2c";
		samsung,check-transdone-int;
		default-clk = <200000000>;
		samsung,scl-clk-stretching;
		samsung,reset-before-trans;
		samsung,i2c-bus-clear = <1>;
		#address-cells = <1>;
		#size-cells = <0>;
		interrupts = <GIC_SPI INTREQ__USI05_I2C IRQ_TYPE_LEVEL_HIGH>;
		samsung,usi-phandle = <&sysreg_peric2_1_usi>;
		samsung,usi-offset = <0x2C>;
		reg = <0x0 0x11980000 0x1000>;
		pinctrl-names = "default", "bus_io";
		pinctrl-0 = <&hsi2c11_bus>;
		pinctrl-1 = <&hsi2c11_bus_io>;
		clocks = <&clock DOUT_DIV_CLK_PERIC2_I2C>, <&clock GATE_PERIC2_CMU_PERIC2_QCH>;
		clock-names = "ipclk_hsi2c", "gate_hsi2c_clk";
		gpio_scl= <&gpp5 2 0x1>;
		gpio_sda= <&gpp5 3 0x1>;
		status = "disabled";
	};

	/* USI06_USI_OIS */
	hsi2c_12: hsi2c@119E0000 {
		compatible = "samsung,exynos5-hsi2c";
		samsung,check-transdone-int;
		default-clk = <200000000>;
		samsung,scl-clk-stretching;
		samsung,reset-before-trans;
		samsung,i2c-bus-clear = <1>;
		#address-cells = <1>;
		#size-cells = <0>;
		interrupts = <GIC_SPI INTREQ__USI06_USI_OIS IRQ_TYPE_LEVEL_HIGH>;
		samsung,usi-phandle = <&sysreg_peric2_1_usi>;
		samsung,usi-offset = <0x180>;
		reg = <0x0 0x119E0000 0x1000>;
		pinctrl-names = "default", "bus_io";
		pinctrl-0 = <&hsi2c12_bus>;
		pinctrl-1 = <&hsi2c12_bus_io>;
		clocks = <&clock DOUT_DIV_CLK_PERIC2_USI06>, <&clock GATE_PERIC2_CMU_PERIC2_QCH>;
		clock-names = "ipclk_hsi2c", "gate_hsi2c_clk";
		gpio_scl= <&gpp6 0 0x1>;
		gpio_sda= <&gpp6 1 0x1>;
		status = "disabled";
	};

	/* USI06_I2C */
	hsi2c_13: hsi2c@11990000 {
		compatible = "samsung,exynos5-hsi2c";
		samsung,check-transdone-int;
		default-clk = <200000000>;
		samsung,scl-clk-stretching;
		samsung,reset-before-trans;
		samsung,i2c-bus-clear = <1>;
		#address-cells = <1>;
		#size-cells = <0>;
		interrupts = <GIC_SPI INTREQ__USI06_I2C IRQ_TYPE_LEVEL_HIGH>;
		samsung,usi-phandle = <&sysreg_peric2_1_usi>;
		samsung,usi-offset = <0x04>;
		reg = <0x0 0x11990000 0x1000>;
		pinctrl-names = "default", "bus_io";
		pinctrl-0 = <&hsi2c13_bus>;
		pinctrl-1 = <&hsi2c13_bus_io>;
		clocks = <&clock DOUT_DIV_CLK_PERIC2_I2C>, <&clock GATE_PERIC2_CMU_PERIC2_QCH>;
		clock-names = "ipclk_hsi2c", "gate_hsi2c_clk";
		gpio_scl= <&gpp6 2 0x1>;
		gpio_sda= <&gpp6 3 0x1>;
		status = "disabled";
	};

	/* USI07_USI */
	hsi2c_14: hsi2c@11050000 {
		compatible = "samsung,exynos5-hsi2c";
		samsung,check-transdone-int;
		default-clk = <200000000>;
		samsung,scl-clk-stretching;
		samsung,reset-before-trans;
		samsung,i2c-bus-clear = <1>;
		#address-cells = <1>;
		#size-cells = <0>;
		interrupts = <GIC_SPI INTREQ__USI07_USI IRQ_TYPE_LEVEL_HIGH>;
		samsung,usi-phandle = <&sysreg_peric1_2_usi>;
		samsung,usi-offset = <0x30>;
		reg = <0x0 0x11050000 0x1000>;
		pinctrl-names = "default", "bus_io";
		pinctrl-0 = <&hsi2c14_bus>;
		pinctrl-1 = <&hsi2c14_bus_io>;
		clocks = <&clock DOUT_DIV_CLK_PERIC1_USI07>, <&clock GATE_PERIC1_CMU_PERIC1_QCH>;
		clock-names = "ipclk_hsi2c", "gate_hsi2c_clk";
		gpio_scl= <&gpp7 0 0x1>;
		gpio_sda= <&gpp7 1 0x1>;
		status = "disabled";
	};

	/* USI07_I2C */
	hsi2c_15: hsi2c@11060000 {
		compatible = "samsung,exynos5-hsi2c";
		samsung,check-transdone-int;
		default-clk = <200000000>;
		samsung,scl-clk-stretching;
		samsung,reset-before-trans;
		samsung,i2c-bus-clear = <1>;
		#address-cells = <1>;
		#size-cells = <0>;
		interrupts = <GIC_SPI INTREQ__USI07_SPI_I2C IRQ_TYPE_LEVEL_HIGH>;
		samsung,usi-phandle = <&sysreg_peric1_2_usi>;
		samsung,usi-offset = <0x34>;
		reg = <0x0 0x11060000 0x1000>;
		pinctrl-names = "default", "bus_io";
		pinctrl-0 = <&hsi2c15_bus>;
		pinctrl-1 = <&hsi2c15_bus_io>;
		clocks = <&clock DOUT_DIV_CLK_PERIC1_USI07_SPI_I2C>, <&clock GATE_PERIC1_CMU_PERIC1_QCH>;
		clock-names = "ipclk_hsi2c", "gate_hsi2c_clk";
		gpio_scl= <&gpp7 2 0x1>;
		gpio_sda= <&gpp7 3 0x1>;
		status = "disabled";
	};

	/* USI08_USI */
	hsi2c_16: hsi2c@11070000 {
		compatible = "samsung,exynos5-hsi2c";
		samsung,check-transdone-int;
		default-clk = <200000000>;
		samsung,scl-clk-stretching;
		samsung,reset-before-trans;
		samsung,i2c-bus-clear = <1>;
		#address-cells = <1>;
		#size-cells = <0>;
		interrupts = <GIC_SPI INTREQ__USI08_USI IRQ_TYPE_LEVEL_HIGH>;
		samsung,usi-phandle = <&sysreg_peric1_2_usi>;
		samsung,usi-offset = <0x38>;
		reg = <0x0 0x11070000 0x1000>;
		pinctrl-names = "default", "bus_io";
		pinctrl-0 = <&hsi2c16_bus>;
		pinctrl-1 = <&hsi2c16_bus_io>;
		clocks = <&clock DOUT_DIV_CLK_PERIC1_USI08>, <&clock GATE_PERIC1_CMU_PERIC1_QCH>;
		clock-names = "ipclk_hsi2c", "gate_hsi2c_clk";
		gpio_scl= <&gpp8 0 0x1>;
		gpio_sda= <&gpp8 1 0x1>;
		status = "disabled";
	};

	/* USI08_I2C */
	hsi2c_17: hsi2c@11080000 {
		compatible = "samsung,exynos5-hsi2c";
		samsung,check-transdone-int;
		default-clk = <200000000>;
		samsung,scl-clk-stretching;
		samsung,reset-before-trans;
		samsung,i2c-bus-clear = <1>;
		#address-cells = <1>;
		#size-cells = <0>;
		interrupts = <GIC_SPI INTREQ__USI08_SPI_I2C IRQ_TYPE_LEVEL_HIGH>;
		samsung,usi-phandle = <&sysreg_peric1_2_usi>;
		samsung,usi-offset = <0x3C>;
		reg = <0x0 0x11080000 0x1000>;
		pinctrl-names = "default", "bus_io";
		pinctrl-0 = <&hsi2c17_bus>;
		pinctrl-1 = <&hsi2c17_bus_io>;
		clocks = <&clock DOUT_DIV_CLK_PERIC1_USI08_SPI_I2C>, <&clock GATE_PERIC1_CMU_PERIC1_QCH>;
		clock-names = "ipclk_hsi2c", "gate_hsi2c_clk";
		gpio_scl= <&gpp8 2 0x1>;
		gpio_sda= <&gpp8 3 0x1>;
		status = "disabled";
	};

	/* USI09_USI */
	hsi2c_18: hsi2c@11090000 {
		compatible = "samsung,exynos5-hsi2c";
		samsung,check-transdone-int;
		default-clk = <200000000>;
		samsung,scl-clk-stretching;
		samsung,reset-before-trans;
		samsung,i2c-bus-clear = <1>;
		#address-cells = <1>;
		#size-cells = <0>;
		interrupts = <GIC_SPI INTREQ__USI09_USI IRQ_TYPE_LEVEL_HIGH>;
		samsung,usi-phandle = <&sysreg_peric1_2_usi>;
		samsung,usi-offset = <0x40>;
		reg = <0x0 0x11090000 0x1000>;
		pinctrl-names = "default", "bus_io";
		pinctrl-0 = <&hsi2c18_bus>;
		pinctrl-1 = <&hsi2c18_bus_io>;
		clocks = <&clock DOUT_DIV_CLK_PERIC1_USI09>, <&clock GATE_PERIC1_CMU_PERIC1_QCH>;
		clock-names = "ipclk_hsi2c", "gate_hsi2c_clk";
		gpio_scl= <&gpp9 0 0x1>;
		gpio_sda= <&gpp9 1 0x1>;
		status = "disabled";
	};

	/* USI09_I2C */
	hsi2c_19: hsi2c@110A0000 {
		compatible = "samsung,exynos5-hsi2c";
		samsung,check-transdone-int;
		default-clk = <200000000>;
		samsung,scl-clk-stretching;
		samsung,reset-before-trans;
		samsung,i2c-bus-clear = <1>;
		#address-cells = <1>;
		#size-cells = <0>;
		interrupts = <GIC_SPI INTREQ__USI09_I2C IRQ_TYPE_LEVEL_HIGH>;
		samsung,usi-phandle = <&sysreg_peric1_2_usi>;
		samsung,usi-offset = <0x44>;
		reg = <0x0 0x110A0000 0x1000>;
		pinctrl-names = "default", "bus_io";
		pinctrl-0 = <&hsi2c19_bus>;
		pinctrl-1 = <&hsi2c19_bus_io>;
		clocks = <&clock DOUT_DIV_CLK_PERIC1_I2C>, <&clock GATE_PERIC1_CMU_PERIC1_QCH>;
		clock-names = "ipclk_hsi2c", "gate_hsi2c_clk";
		gpio_scl= <&gpp9 2 0x1>;
		gpio_sda= <&gpp9 3 0x1>;
		status = "disabled";
	};

	/* USI10_USI */
	hsi2c_20: hsi2c@110C0000 {
		compatible = "samsung,exynos5-hsi2c";
		samsung,check-transdone-int;
		default-clk = <200000000>;
		samsung,scl-clk-stretching;
		samsung,reset-before-trans;
		samsung,i2c-bus-clear = <1>;
		#address-cells = <1>;
		#size-cells = <0>;
		interrupts = <GIC_SPI INTREQ__USI10_USI IRQ_TYPE_LEVEL_HIGH>;
		samsung,usi-phandle = <&sysreg_peric1_1_usi>;
		samsung,usi-offset = <0x10>;
		reg = <0x0 0x110C0000 0x1000>;
		pinctrl-names = "default", "bus_io";
		pinctrl-0 = <&hsi2c20_bus>;
		pinctrl-1 = <&hsi2c20_bus_io>;
		clocks = <&clock DOUT_DIV_CLK_PERIC1_USI10>, <&clock GATE_PERIC1_CMU_PERIC1_QCH>;
		clock-names = "ipclk_hsi2c", "gate_hsi2c_clk";
		gpio_scl= <&gpp10 0 0x1>;
		gpio_sda= <&gpp10 1 0x1>;
		status = "disabled";
	};

	/* USI10_I2C */
	hsi2c_21: hsi2c@110D0000 {
		compatible = "samsung,exynos5-hsi2c";
		samsung,check-transdone-int;
		default-clk = <200000000>;
		samsung,scl-clk-stretching;
		samsung,reset-before-trans;
		samsung,i2c-bus-clear = <1>;
		#address-cells = <1>;
		#size-cells = <0>;
		interrupts = <GIC_SPI INTREQ__USI10_I2C IRQ_TYPE_LEVEL_HIGH>;
		samsung,usi-phandle = <&sysreg_peric1_1_usi>;
		samsung,usi-offset = <0x14>;
		reg = <0x0 0x110D0000 0x1000>;
		pinctrl-names = "default", "bus_io";
		pinctrl-0 = <&hsi2c21_bus>;
		pinctrl-1 = <&hsi2c21_bus_io>;
		clocks = <&clock DOUT_DIV_CLK_PERIC1_I2C>, <&clock GATE_PERIC1_CMU_PERIC1_QCH>;
		clock-names = "ipclk_hsi2c", "gate_hsi2c_clk";
		gpio_scl= <&gpp10 2 0x1>;
		gpio_sda= <&gpp10 3 0x1>;
		status = "disabled";
	};

	/* USI11_USI */
	hsi2c_22: hsi2c@119A0000 {
		compatible = "samsung,exynos5-hsi2c";
		samsung,check-transdone-int;
		default-clk = <200000000>;
		samsung,scl-clk-stretching;
		samsung,reset-before-trans;
		samsung,i2c-bus-clear = <1>;
		#address-cells = <1>;
		#size-cells = <0>;
		interrupts = <GIC_SPI INTREQ__USI11_USI IRQ_TYPE_LEVEL_HIGH>;
		samsung,usi-phandle = <&sysreg_peric2_1_usi>;
		samsung,usi-offset = <0x58>;
		reg = <0x0 0x119A0000 0x1000>;
		pinctrl-names = "default", "bus_io";
		pinctrl-0 = <&hsi2c22_bus>;
		pinctrl-1 = <&hsi2c22_bus_io>;
		clocks = <&clock DOUT_DIV_CLK_PERIC2_USI11>, <&clock GATE_PERIC2_CMU_PERIC2_QCH>;
		clock-names = "ipclk_hsi2c", "gate_hsi2c_clk";
		gpio_scl= <&gpp11 0 0x1>;
		gpio_sda= <&gpp11 1 0x1>;
		status = "disabled";
	};

	/* USI11_I2C */
	hsi2c_23: hsi2c@119B0000 {
		compatible = "samsung,exynos5-hsi2c";
		samsung,check-transdone-int;
		default-clk = <200000000>;
		samsung,scl-clk-stretching;
		samsung,reset-before-trans;
		samsung,i2c-bus-clear = <1>;
		#address-cells = <1>;
		#size-cells = <0>;
		interrupts = <GIC_SPI INTREQ__USI11_I2C IRQ_TYPE_LEVEL_HIGH>;
		samsung,usi-phandle = <&sysreg_peric2_1_usi>;
		samsung,usi-offset = <0x5C>;
		reg = <0x0 0x119B0000 0x1000>;
		pinctrl-names = "default", "bus_io";
		pinctrl-0 = <&hsi2c23_bus>;
		pinctrl-1 = <&hsi2c23_bus_io>;
		clocks = <&clock DOUT_DIV_CLK_PERIC2_I2C>, <&clock GATE_PERIC2_CMU_PERIC2_QCH>;
		clock-names = "ipclk_hsi2c", "gate_hsi2c_clk";
		gpio_scl= <&gpp11 2 0x1>;
		gpio_sda= <&gpp11 3 0x1>;
		status = "disabled";
	};

	/* USI12_I2C */
	hsi2c_24: hsi2c@10940000 {
		compatible = "samsung,exynos5-hsi2c";
		samsung,check-transdone-int;
		default-clk = <200000000>;
		samsung,scl-clk-stretching;
		samsung,reset-before-trans;
		samsung,i2c-bus-clear = <1>;
		#address-cells = <1>;
		#size-cells = <0>;
		interrupts = <GIC_SPI INTREQ__USI12_I2C IRQ_TYPE_LEVEL_HIGH>;
		samsung,usi-phandle = <&sysreg_peric0_2_usi>;
		samsung,usi-offset = <0x2C>;
		reg = <0x0 0x10940000 0x1000>;
		pinctrl-names = "default", "bus_io";
		pinctrl-0 = <&hsi2c24_bus>;
		pinctrl-1 = <&hsi2c24_bus_io>;
		clocks = <&clock DOUT_DIV_CLK_PERIC0_I2C>, <&clock GATE_PERIC0_CMU_PERIC0_QCH>;
		clock-names = "ipclk_hsi2c", "gate_hsi2c_clk";
		gpio_scl= <&gpc0 0 0x1>;
		gpio_sda= <&gpc0 1 0x1>;
		status = "disabled";
	};

	/* USI13_I2C */
	hsi2c_25: hsi2c@10950000 {
		compatible = "samsung,exynos5-hsi2c";
		samsung,check-transdone-int;
		default-clk = <200000000>;
		samsung,scl-clk-stretching;
		samsung,reset-before-trans;
		samsung,i2c-bus-clear = <1>;
		#address-cells = <1>;
		#size-cells = <0>;
		interrupts = <GIC_SPI INTREQ__USI13_I2C IRQ_TYPE_LEVEL_HIGH>;
		samsung,usi-phandle = <&sysreg_peric0_2_usi>;
		samsung,usi-offset = <0x34>;
		reg = <0x0 0x10950000 0x1000>;
		pinctrl-names = "default", "bus_io";
		pinctrl-0 = <&hsi2c25_bus>;
		pinctrl-1 = <&hsi2c25_bus_io>;
		clocks = <&clock DOUT_DIV_CLK_PERIC0_I2C>, <&clock GATE_PERIC0_CMU_PERIC0_QCH>;
		clock-names = "ipclk_hsi2c", "gate_hsi2c_clk";
		gpio_scl= <&gpc1 0 0x1>;
		gpio_sda= <&gpc1 1 0x1>;
		status = "disabled";
	};

	/* USI14_I2C */
	hsi2c_26: hsi2c@110E0000 {
		compatible = "samsung,exynos5-hsi2c";
		samsung,check-transdone-int;
		default-clk = <200000000>;
		samsung,scl-clk-stretching;
		samsung,reset-before-trans;
		samsung,i2c-bus-clear = <1>;
		#address-cells = <1>;
		#size-cells = <0>;
		interrupts = <GIC_SPI INTREQ__USI14_I2C IRQ_TYPE_LEVEL_HIGH>;
		samsung,usi-phandle = <&sysreg_peric1_1_usi>;
		samsung,usi-offset = <0x18>;
		reg = <0x0 0x110E0000 0x1000>;
		pinctrl-names = "default", "bus_io";
		pinctrl-0 = <&hsi2c26_bus>;
		pinctrl-1 = <&hsi2c26_bus_io>;
		clocks = <&clock DOUT_DIV_CLK_PERIC1_I2C>, <&clock GATE_PERIC1_CMU_PERIC1_QCH>;
		clock-names = "ipclk_hsi2c", "gate_hsi2c_clk";
		gpio_scl= <&gpc2 0 0x1>;
		gpio_sda= <&gpc2 1 0x1>;
		status = "disabled";
	};

	/* USI15_I2C */
	hsi2c_27: hsi2c@110F0000 {
		compatible = "samsung,exynos5-hsi2c";
		samsung,check-transdone-int;
		default-clk = <200000000>;
		samsung,scl-clk-stretching;
		samsung,reset-before-trans;
		samsung,i2c-bus-clear = <1>;
		#address-cells = <1>;
		#size-cells = <0>;
		interrupts = <GIC_SPI INTREQ__USI15_I2C IRQ_TYPE_LEVEL_HIGH>;
		samsung,usi-phandle = <&sysreg_peric1_1_usi>;
		samsung,usi-offset = <0x1C>;
		reg = <0x0 0x110F0000 0x1000>;
		pinctrl-names = "default", "bus_io";
		pinctrl-0 = <&hsi2c27_bus>;
		pinctrl-1 = <&hsi2c27_bus_io>;
		clocks = <&clock DOUT_DIV_CLK_PERIC1_I2C>, <&clock GATE_PERIC1_CMU_PERIC1_QCH>;
		clock-names = "ipclk_hsi2c", "gate_hsi2c_clk";
		gpio_scl= <&gpc4 0 0x1>;
		gpio_sda= <&gpc4 1 0x1>;
		status = "disabled";
	};

	/* USI16_I2C */
	hsi2c_28: hsi2c@11100000 {
		compatible = "samsung,exynos5-hsi2c";
		samsung,check-transdone-int;
		default-clk = <200000000>;
		samsung,scl-clk-stretching;
		samsung,reset-before-trans;
		samsung,i2c-bus-clear = <1>;
		#address-cells = <1>;
		#size-cells = <0>;
		interrupts = <GIC_SPI INTREQ__USI16_I2C IRQ_TYPE_LEVEL_HIGH>;
		samsung,usi-phandle = <&sysreg_peric1_1_usi>;
		samsung,usi-offset = <0x20>;
		reg = <0x0 0x11100000 0x1000>;
		pinctrl-names = "default", "bus_io";
		pinctrl-0 = <&hsi2c28_bus>;
		pinctrl-1 = <&hsi2c28_bus_io>;
		clocks = <&clock DOUT_DIV_CLK_PERIC1_I2C>, <&clock GATE_PERIC1_CMU_PERIC1_QCH>;
		clock-names = "ipclk_hsi2c", "gate_hsi2c_clk";
		gpio_scl= <&gpc5 0 0x1>;
		gpio_sda= <&gpc5 1 0x1>;
		status = "disabled";
	};

	/* USI17_I2C */
	hsi2c_29: hsi2c@11850000 {
		compatible = "samsung,exynos5-hsi2c";
		samsung,check-transdone-int;
		default-clk = <200000000>;
		samsung,scl-clk-stretching;
		samsung,reset-before-trans;
		samsung,i2c-bus-clear = <1>;
		#address-cells = <1>;
		#size-cells = <0>;
		interrupts = <GIC_SPI INTREQ__USI17_I2C IRQ_TYPE_LEVEL_HIGH>;
		samsung,usi-phandle = <&sysreg_peric2_1_usi>;
		samsung,usi-offset = <0x60>;
		reg = <0x0 0x11850000 0x1000>;
		pinctrl-names = "default", "bus_io";
		pinctrl-0 = <&hsi2c29_bus>;
		pinctrl-1 = <&hsi2c29_bus_io>;
		clocks = <&clock DOUT_DIV_CLK_PERIC2_I2C>, <&clock GATE_PERIC2_CMU_PERIC2_QCH>;
		clock-names = "ipclk_hsi2c", "gate_hsi2c_clk";
		gpio_scl= <&gpc3 0 0x1>;
		gpio_sda= <&gpc3 1 0x1>;
		status = "disabled";
	};

	/* USI18_I2C */
	hsi2c_30: hsi2c@11860000 {
		compatible = "samsung,exynos5-hsi2c";
		samsung,check-transdone-int;
		default-clk = <200000000>;
		samsung,scl-clk-stretching;
		samsung,reset-before-trans;
		samsung,i2c-bus-clear = <1>;
		#address-cells = <1>;
		#size-cells = <0>;
		interrupts = <GIC_SPI INTREQ__USI18_I2C IRQ_TYPE_LEVEL_HIGH>;
		samsung,usi-phandle = <&sysreg_peric2_1_usi>;
		samsung,usi-offset = <0x64>;
		reg = <0x0 0x11860000 0x1000>;
		pinctrl-names = "default", "bus_io";
		pinctrl-0 = <&hsi2c30_bus>;
		pinctrl-1 = <&hsi2c30_bus_io>;
		clocks = <&clock DOUT_DIV_CLK_PERIC2_I2C>, <&clock GATE_PERIC2_CMU_PERIC2_QCH>;
		clock-names = "ipclk_hsi2c", "gate_hsi2c_clk";
		gpio_scl= <&gpc6 0 0x1>;
		gpio_sda= <&gpc6 1 0x1>;
		status = "disabled";
	};

	/* USI19_I2C */
	hsi2c_31: hsi2c@11870000 {
		compatible = "samsung,exynos5-hsi2c";
		samsung,check-transdone-int;
		default-clk = <200000000>;
		samsung,scl-clk-stretching;
		samsung,reset-before-trans;
		samsung,i2c-bus-clear = <1>;
		#address-cells = <1>;
		#size-cells = <0>;
		interrupts = <GIC_SPI INTREQ__USI19_I2C IRQ_TYPE_LEVEL_HIGH>;
		samsung,usi-phandle = <&sysreg_peric2_1_usi>;
		samsung,usi-offset = <0x68>;
		reg = <0x0 0x11870000 0x1000>;
		pinctrl-names = "default", "bus_io";
		pinctrl-0 = <&hsi2c31_bus>;
		pinctrl-1 = <&hsi2c31_bus_io>;
		clocks = <&clock DOUT_DIV_CLK_PERIC2_I2C>, <&clock GATE_PERIC2_CMU_PERIC2_QCH>;
		clock-names = "ipclk_hsi2c", "gate_hsi2c_clk";
		gpio_scl= <&gpc7 0 0x1>;
		gpio_sda= <&gpc7 1 0x1>;
		status = "disabled";
	};

	/* USI20_I2C */
	hsi2c_32: hsi2c@11880000 {
		compatible = "samsung,exynos5-hsi2c";
		samsung,check-transdone-int;
		default-clk = <200000000>;
		samsung,scl-clk-stretching;
		samsung,reset-before-trans;
		samsung,i2c-bus-clear = <1>;
		#address-cells = <1>;
		#size-cells = <0>;
		interrupts = <GIC_SPI INTREQ__USI20_I2C IRQ_TYPE_LEVEL_HIGH>;
		samsung,usi-phandle = <&sysreg_peric2_1_usi>;
		samsung,usi-offset = <0x6C>;
		reg = <0x0 0x11880000 0x1000>;
		pinctrl-names = "default", "bus_io";
		pinctrl-0 = <&hsi2c32_bus>;
		pinctrl-1 = <&hsi2c32_bus_io>;
		clocks = <&clock DOUT_DIV_CLK_PERIC2_I2C>, <&clock GATE_PERIC2_CMU_PERIC2_QCH>;
		clock-names = "ipclk_hsi2c", "gate_hsi2c_clk";
		gpio_scl= <&gpc8 0 0x1>;
		gpio_sda= <&gpc8 1 0x1>;
		status = "disabled";
	};

	/* USI21_I2C */
	hsi2c_33: hsi2c@11890000 {
		compatible = "samsung,exynos5-hsi2c";
		samsung,check-transdone-int;
		default-clk = <200000000>;
		samsung,scl-clk-stretching;
		samsung,reset-before-trans;
		samsung,i2c-bus-clear = <1>;
		#address-cells = <1>;
		#size-cells = <0>;
		interrupts = <GIC_SPI INTREQ__USI21_I2C IRQ_TYPE_LEVEL_HIGH>;
		samsung,usi-phandle = <&sysreg_peric2_1_usi>;
		samsung,usi-offset = <0x70>;
		reg = <0x0 0x11890000 0x1000>;
		pinctrl-names = "default", "bus_io";
		pinctrl-0 = <&hsi2c33_bus>;
		pinctrl-1 = <&hsi2c33_bus_io>;
		clocks = <&clock DOUT_DIV_CLK_PERIC2_I2C>, <&clock GATE_PERIC2_CMU_PERIC2_QCH>;
		clock-names = "ipclk_hsi2c", "gate_hsi2c_clk";
		gpio_scl= <&gpc9 0 0x1>;
		gpio_sda= <&gpc9 1 0x1>;
		status = "disabled";
	};

	/* PERIC1_I2C */
	hsi2c_34: hsi2c@110B0000 {
		compatible = "samsung,exynos5-hsi2c";
		samsung,check-transdone-int;
		default-clk = <200000000>;
		samsung,scl-clk-stretching;
		samsung,reset-before-trans;
		samsung,i2c-bus-clear = <1>;
		#address-cells = <1>;
		#size-cells = <0>;
		interrupts = <GIC_SPI INTREQ__PERIC1_I2C IRQ_TYPE_LEVEL_HIGH>;
		samsung,usi-phandle = <&sysreg_peric1_2_usi>;
		samsung,usi-offset = <0x4C>;
		reg = <0x0 0x110B0000 0x1000>;
		pinctrl-names = "default", "bus_io";
		pinctrl-0 = <&hsi2c34_bus>;
		pinctrl-1 = <&hsi2c34_bus_io>;
		clocks = <&clock DOUT_DIV_CLK_PERIC1_I2C>, <&clock GATE_PERIC1_CMU_PERIC1_QCH>;
		clock-names = "ipclk_hsi2c", "gate_hsi2c_clk";
		gpio_scl= <&gpc10 0 0x1>;
		gpio_sda= <&gpc10 1 0x1>;
		status = "disabled";
	};

	/* USI_CMGP00 */
	hsi2c_35: hsi2c@15100000 {
		compatible = "samsung,exynos5-hsi2c";
		samsung,check-transdone-int;
		default-clk = <200000000>;
		samsung,scl-clk-stretching;
		samsung,reset-before-trans;
		samsung,i2c-bus-clear = <1>;
		#address-cells = <1>;
		#size-cells = <0>;
		interrupts = <GIC_SPI INTREQ__USI_CMGP0 IRQ_TYPE_LEVEL_HIGH>;
		samsung,usi-phandle = <&sysreg_cmgp_usi>;
		samsung,usi-offset = <0x00>;
		reg = <0x0 0x15100000 0x1000>;
		pinctrl-names = "default", "bus_io";
		pinctrl-0 = <&hsi2c35_bus>;
		pinctrl-1 = <&hsi2c35_bus_io>;
		clocks = <&clock DOUT_DIV_CLK_CMGP_USI0>, <&clock GATE_USI_CMGP0_QCH>;
		clock-names = "ipclk_hsi2c", "gate_hsi2c_clk";
		gpio_scl= <&gpm0 0 0x1>;
		gpio_sda= <&gpm1 0 0x1>;
		status = "disabled";
	};

	/* SPI_I2C_CMGP00 */
	hsi2c_36: hsi2c@15110000 {
		compatible = "samsung,exynos5-hsi2c";
		samsung,check-transdone-int;
		default-clk = <200000000>;
		samsung,scl-clk-stretching;
		samsung,reset-before-trans;
		samsung,i2c-bus-clear = <1>;
		#address-cells = <1>;
		#size-cells = <0>;
		interrupts = <GIC_SPI INTREQ__SPI_I2C_CMGP0 IRQ_TYPE_LEVEL_HIGH>;
		samsung,usi-phandle = <&sysreg_cmgp_usi>;
		samsung,usi-offset = <0x70>;
		reg = <0x0 0x15110000 0x1000>;
		pinctrl-names = "default", "bus_io";
		pinctrl-0 = <&hsi2c36_bus>;
		pinctrl-1 = <&hsi2c36_bus_io>;
		clocks = <&clock DOUT_DIV_CLK_CMGP_SPI_I2C0>, <&clock GATE_SPI_I2C_CMGP0_QCH>;
		clock-names = "ipclk_hsi2c", "gate_hsi2c_clk";
		gpio_scl= <&gpm2 0 0x1>;
		gpio_sda= <&gpm3 0 0x1>;
		status = "disabled";
	};

	/* USI_CMGP01 */
	hsi2c_37: hsi2c@15120000 {
		compatible = "samsung,exynos5-hsi2c";
		samsung,check-transdone-int;
		default-clk = <200000000>;
		samsung,scl-clk-stretching;
		samsung,reset-before-trans;
		samsung,i2c-bus-clear = <1>;
		#address-cells = <1>;
		#size-cells = <0>;
		interrupts = <GIC_SPI INTREQ__USI_CMGP1 IRQ_TYPE_LEVEL_HIGH>;
		samsung,usi-phandle = <&sysreg_cmgp_usi>;
		samsung,usi-offset = <0x10>;
		reg = <0x0 0x15120000 0x1000>;
		pinctrl-names = "default", "bus_io";
		pinctrl-0 = <&hsi2c37_bus>;
		pinctrl-1 = <&hsi2c37_bus_io>;
		clocks = <&clock DOUT_DIV_CLK_CMGP_USI1>, <&clock GATE_USI_CMGP1_QCH>;
		clock-names = "ipclk_hsi2c", "gate_hsi2c_clk";
		gpio_scl= <&gpm4 0 0x1>;
		gpio_sda= <&gpm5 0 0x1>;
		status = "disabled";
	};

	/* SPI_I2C_CMGP01 */
	hsi2c_38: hsi2c@15130000 {
		compatible = "samsung,exynos5-hsi2c";
		samsung,check-transdone-int;
		default-clk = <200000000>;
		samsung,scl-clk-stretching;
		samsung,reset-before-trans;
		samsung,i2c-bus-clear = <1>;
		#address-cells = <1>;
		#size-cells = <0>;
		interrupts = <GIC_SPI INTREQ__SPI_I2C_CMGP1 IRQ_TYPE_LEVEL_HIGH>;
		samsung,usi-phandle = <&sysreg_cmgp_usi>;
		samsung,usi-offset = <0x74>;
		reg = <0x0 0x15130000 0x1000>;
		pinctrl-names = "default", "bus_io";
		pinctrl-0 = <&hsi2c38_bus>;
		pinctrl-1 = <&hsi2c38_bus_io>;
		clocks = <&clock DOUT_DIV_CLK_CMGP_SPI_I2C1>, <&clock GATE_SPI_I2C_CMGP1_QCH>;
		clock-names = "ipclk_hsi2c", "gate_hsi2c_clk";
		gpio_scl= <&gpm6 0 0x1>;
		gpio_sda= <&gpm7 0 0x1>;
		status = "disabled";
	};

	/* USI_CMGP02 */
	hsi2c_39: hsi2c@15140000 {
		compatible = "samsung,exynos5-hsi2c";
		samsung,check-transdone-int;
		default-clk = <200000000>;
		samsung,scl-clk-stretching;
		samsung,reset-before-trans;
		samsung,i2c-bus-clear = <1>;
		#address-cells = <1>;
		#size-cells = <0>;
		interrupts = <GIC_SPI INTREQ__USI_CMGP2 IRQ_TYPE_LEVEL_HIGH>;
		samsung,usi-phandle = <&sysreg_cmgp_usi>;
		samsung,usi-offset = <0x20>;
		reg = <0x0 0x15140000 0x1000>;
		pinctrl-names = "default", "bus_io";
		pinctrl-0 = <&hsi2c39_bus>;
		pinctrl-1 = <&hsi2c39_bus_io>;
		clocks = <&clock DOUT_DIV_CLK_CMGP_USI2>, <&clock GATE_USI_CMGP2_QCH>;
		clock-names = "ipclk_hsi2c", "gate_hsi2c_clk";
		gpio_scl= <&gpm8 0 0x1>;
		gpio_sda= <&gpm9 0 0x1>;
		status = "disabled";
	};

	/* I2C_CMGP02 */
	hsi2c_40: hsi2c@15150000 {
		compatible = "samsung,exynos5-hsi2c";
		samsung,check-transdone-int;
		default-clk = <200000000>;
		samsung,scl-clk-stretching;
		samsung,reset-before-trans;
		samsung,i2c-bus-clear = <1>;
		#address-cells = <1>;
		#size-cells = <0>;
		interrupts = <GIC_SPI INTREQ__I2C_CMGP2 IRQ_TYPE_LEVEL_HIGH>;
		samsung,usi-phandle = <&sysreg_cmgp_usi>;
		samsung,usi-offset = <0x24>;
		reg = <0x0 0x15150000 0x1000>;
		pinctrl-names = "default", "bus_io";
		pinctrl-0 = <&hsi2c40_bus>;
		pinctrl-1 = <&hsi2c40_bus_io>;
		clocks = <&clock DOUT_DIV_CLK_CMGP_I2C>, <&clock GATE_I2C_CMGP2_QCH>;
		clock-names = "ipclk_hsi2c", "gate_hsi2c_clk";
		gpio_scl= <&gpm10 0 0x1>;
		gpio_sda= <&gpm11 0 0x1>;
		status = "disabled";
	};

	/* USI_CMGP03 */
	hsi2c_41: hsi2c@15160000 {
		compatible = "samsung,exynos5-hsi2c";
		samsung,check-transdone-int;
		default-clk = <200000000>;
		samsung,scl-clk-stretching;
		samsung,reset-before-trans;
		samsung,i2c-bus-clear = <1>;
		#address-cells = <1>;
		#size-cells = <0>;
		interrupts = <GIC_SPI INTREQ__USI_CMGP3 IRQ_TYPE_LEVEL_HIGH>;
		samsung,usi-phandle = <&sysreg_cmgp_usi>;
		samsung,usi-offset = <0x30>;
		reg = <0x0 0x15160000 0x1000>;
		pinctrl-names = "default", "bus_io";
		pinctrl-0 = <&hsi2c41_bus>;
		pinctrl-1 = <&hsi2c41_bus_io>;
		clocks = <&clock DOUT_DIV_CLK_CMGP_USI3>, <&clock GATE_USI_CMGP3_QCH>;
		clock-names = "ipclk_hsi2c", "gate_hsi2c_clk";
		gpio_scl= <&gpm12 0 0x1>;
		gpio_sda= <&gpm13 0 0x1>;
		status = "disabled";
	};

	/* I2C_CMGP03 */
/*
	hsi2c_42: hsi2c@15170000 {
		compatible = "samsung,exynos5-hsi2c";
		samsung,check-transdone-int;
		default-clk = <200000000>;
		samsung,scl-clk-stretching;
		samsung,reset-before-trans;
		samsung,i2c-bus-clear = <1>;
		#address-cells = <1>;
		#size-cells = <0>;
		interrupts = <GIC_SPI INTREQ__I2C_CMGP3 IRQ_TYPE_LEVEL_HIGH>;
		samsung,usi-phandle = <&sysreg_cmgp_usi>;
		samsung,usi-offset = <0x34>;
		reg = <0x0 0x15170000 0x1000>;
		pinctrl-names = "default", "bus_io";
		pinctrl-0 = <&hsi2c42_bus>;
		pinctrl-1 = <&hsi2c42_bus_io>;
		clocks = <&clock DOUT_DIV_CLK_CMGP_I2C>, <&clock GATE_I2C_CMGP3_QCH>;
		clock-names = "ipclk_hsi2c", "gate_hsi2c_clk";
		gpio_scl= <&gpm14 0 0x1>;
		gpio_sda= <&gpm15 0 0x1>;
		status = "disabled";
	};
*/
	/* USI_CMGP04 */
	hsi2c_43: hsi2c@15180000 {
		compatible = "samsung,exynos5-hsi2c";
		samsung,check-transdone-int;
		default-clk = <200000000>;
		samsung,scl-clk-stretching;
		samsung,reset-before-trans;
		samsung,i2c-bus-clear = <1>;
		#address-cells = <1>;
		#size-cells = <0>;
		interrupts = <GIC_SPI INTREQ__USI_CMGP4 IRQ_TYPE_LEVEL_HIGH>;
		samsung,usi-phandle = <&sysreg_cmgp_usi>;
		samsung,usi-offset = <0x40>;
		reg = <0x0 0x15180000 0x1000>;
		pinctrl-names = "default", "bus_io";
		pinctrl-0 = <&hsi2c43_bus>;
		pinctrl-1 = <&hsi2c43_bus_io>;
		clocks = <&clock DOUT_DIV_CLK_CMGP_USI4>, <&clock GATE_USI_CMGP4_QCH>;
		clock-names = "ipclk_hsi2c", "gate_hsi2c_clk";
		gpio_scl= <&gpm16 0 0x1>;
		gpio_sda= <&gpm17 0 0x1>;
		status = "disabled";
	};

	/* I2C_CMGP04 */
	hsi2c_44: hsi2c@15190000 {
		compatible = "samsung,exynos5-hsi2c";
		samsung,check-transdone-int;
		default-clk = <200000000>;
		samsung,scl-clk-stretching;
		samsung,reset-before-trans;
		samsung,i2c-bus-clear = <1>;
		#address-cells = <1>;
		#size-cells = <0>;
		interrupts = <GIC_SPI INTREQ__I2C_CMGP4 IRQ_TYPE_LEVEL_HIGH>;
		samsung,usi-phandle = <&sysreg_cmgp_usi>;
		samsung,usi-offset = <0x44>;
		reg = <0x0 0x15190000 0x1000>;
		pinctrl-names = "default", "bus_io";
		pinctrl-0 = <&hsi2c44_bus>;
		pinctrl-1 = <&hsi2c44_bus_io>;
		clocks = <&clock DOUT_DIV_CLK_CMGP_I2C>, <&clock GATE_I2C_CMGP4_QCH>;
		clock-names = "ipclk_hsi2c", "gate_hsi2c_clk";
		gpio_scl= <&gpm18 0 0x1>;
		gpio_sda= <&gpm19 0 0x1>;
		status = "disabled";
	};

	/* USI_CMGP05 */
	hsi2c_45: hsi2c@151A0000 {
		compatible = "samsung,exynos5-hsi2c";
		samsung,check-transdone-int;
		default-clk = <200000000>;
		samsung,scl-clk-stretching;
		samsung,reset-before-trans;
		samsung,i2c-bus-clear = <1>;
		#address-cells = <1>;
		#size-cells = <0>;
		interrupts = <GIC_SPI INTREQ__USI_CMGP5 IRQ_TYPE_LEVEL_HIGH>;
		samsung,usi-phandle = <&sysreg_cmgp_usi>;
		samsung,usi-offset = <0x50>;
		reg = <0x0 0x151A0000 0x1000>;
		pinctrl-names = "default", "bus_io";
		pinctrl-0 = <&hsi2c45_bus>;
		pinctrl-1 = <&hsi2c45_bus_io>;
		clocks = <&clock DOUT_DIV_CLK_CMGP_USI5>, <&clock GATE_USI_CMGP5_QCH>;
		clock-names = "ipclk_hsi2c", "gate_hsi2c_clk";
		gpio_scl= <&gpm20 0 0x1>;
		gpio_sda= <&gpm21 0 0x1>;
		status = "disabled";
	};

	/* I2C_CMGP05 */
	hsi2c_46: hsi2c@151B0000 {
		compatible = "samsung,exynos5-hsi2c";
		samsung,check-transdone-int;
		default-clk = <200000000>;
		samsung,scl-clk-stretching;
		samsung,reset-before-trans;
		samsung,i2c-bus-clear = <1>;
		#address-cells = <1>;
		#size-cells = <0>;
		interrupts = <GIC_SPI INTREQ__I2C_CMGP5 IRQ_TYPE_LEVEL_HIGH>;
		samsung,usi-phandle = <&sysreg_cmgp_usi>;
		samsung,usi-offset = <0x54>;
		reg = <0x0 0x151B0000 0x1000>;
		pinctrl-names = "default", "bus_io";
		pinctrl-0 = <&hsi2c46_bus>;
		pinctrl-1 = <&hsi2c46_bus_io>;
		clocks = <&clock DOUT_DIV_CLK_CMGP_I2C>, <&clock GATE_I2C_CMGP5_QCH>;
		clock-names = "ipclk_hsi2c", "gate_hsi2c_clk";
		gpio_scl= <&gpm22 0 0x1>;
		gpio_sda= <&gpm23 0 0x1>;
		status = "disabled";
	};

	/* USI_CMGP06 */
	hsi2c_47: hsi2c@151C0000 {
		compatible = "samsung,exynos5-hsi2c";
		samsung,check-transdone-int;
		default-clk = <200000000>;
		samsung,scl-clk-stretching;
		samsung,reset-before-trans;
		samsung,i2c-bus-clear = <1>;
		#address-cells = <1>;
		#size-cells = <0>;
		interrupts = <GIC_SPI INTREQ__USI_CMGP6 IRQ_TYPE_LEVEL_HIGH>;
		samsung,usi-phandle = <&sysreg_cmgp_usi>;
		samsung,usi-offset = <0x60>;
		reg = <0x0 0x151C0000 0x1000>;
		pinctrl-names = "default", "bus_io";
		pinctrl-0 = <&hsi2c47_bus>;
		pinctrl-1 = <&hsi2c47_bus_io>;
		clocks = <&clock DOUT_DIV_CLK_CMGP_USI6>, <&clock GATE_USI_CMGP6_QCH>;
		clock-names = "ipclk_hsi2c", "gate_hsi2c_clk";
		gpio_scl= <&gpm24 0 0x1>;
		gpio_sda= <&gpm25 0 0x1>;
		status = "disabled";
	};

	/* I2C_CMGP06 */
	hsi2c_48: hsi2c@151D0000 {
		compatible = "samsung,exynos5-hsi2c";
		samsung,check-transdone-int;
		default-clk = <200000000>;
		samsung,scl-clk-stretching;
		samsung,reset-before-trans;
		samsung,i2c-bus-clear = <1>;
		#address-cells = <1>;
		#size-cells = <0>;
		interrupts = <GIC_SPI INTREQ__I2C_CMGP6 IRQ_TYPE_LEVEL_HIGH>;
		samsung,usi-phandle = <&sysreg_cmgp_usi>;
		samsung,usi-offset = <0x64>;
		reg = <0x0 0x151D0000 0x1000>;
		pinctrl-names = "default", "bus_io";
		pinctrl-0 = <&hsi2c48_bus>;
		pinctrl-1 = <&hsi2c48_bus_io>;
		clocks = <&clock DOUT_DIV_CLK_CMGP_I2C>, <&clock GATE_I2C_CMGP6_QCH>;
		clock-names = "ipclk_hsi2c", "gate_hsi2c_clk";
		gpio_scl= <&gpm26 0 0x1>;
		gpio_sda= <&gpm27 0 0x1>;
		status = "disabled";
	};

	/* USI00_USI */
	spi_0: spi@11900000 {
		compatible = "samsung,exynos-spi";
		samsung,spi-fifosize = <64>;
		swap-mode = <1>;
		#address-cells = <1>;
		#size-cells = <0>;
/*
		dma-mode;
*/
		dmas = <&pdma0 1 &pdma0 0>;
		dma-names = "tx", "rx";
		samsung,dma-phandle = <&sysreg_pdma_peri_sel>;
		samsung,dma-offset-tx = <1>;
		samsung,dma-offset-rx = <0>;
		samsung,dma-value = <1>;
		interrupts = <GIC_SPI INTREQ__USI00_USI IRQ_TYPE_LEVEL_HIGH>;
		samsung,usi-phandle = <&sysreg_peric2_2_usi>;
		samsung,usi-offset = <0x00>;
		samsung,usi-version = <3>;
		clocks = <&clock GATE_PERIC2_CMU_PERIC2_QCH>, <&clock DOUT_DIV_CLK_PERIC2_USI00>;
		clock-names = "gate_spi_clk", "ipclk_spi";
		pinctrl-names = "default";
		pinctrl-0 = <&spi0_bus>;
		reg = <0x0 0x11900000 0x1000>;
		status = "disabled";
	};

	/* USI01_USI */
	spi_1: spi@11920000 {
		compatible = "samsung,exynos-spi";
		samsung,spi-fifosize = <64>;
		swap-mode = <1>;
		#address-cells = <1>;
		#size-cells = <0>;
/*
		dma-mode;
*/
		dmas = <&pdma0 3 &pdma0 2>;
		dma-names = "tx", "rx";
		samsung,dma-phandle = <&sysreg_pdma_peri_sel>;
		samsung,dma-offset-tx = <3>;
		samsung,dma-offset-rx = <2>;
		samsung,dma-value = <1>;
		interrupts = <GIC_SPI INTREQ__USI01_USI IRQ_TYPE_LEVEL_HIGH>;
		samsung,usi-phandle = <&sysreg_peric2_2_usi>;
		samsung,usi-offset = <0x08>;
		samsung,usi-version = <3>;
		clocks = <&clock GATE_PERIC2_CMU_PERIC2_QCH>, <&clock DOUT_DIV_CLK_PERIC2_USI01>;
		clock-names = "gate_spi_clk", "ipclk_spi";
		pinctrl-names = "default";
		pinctrl-0 = <&spi1_bus>;
		reg = <0x0 0x11920000 0x1000>;
		status = "disabled";
	};

	/* USI02_USI */
	spi_2: spi@11940000 {
		compatible = "samsung,exynos-spi";
		samsung,spi-fifosize = <256>;
		swap-mode = <1>;
		#address-cells = <1>;
		#size-cells = <0>;
/*
		dma-mode;
*/
		dmas = <&pdma0 5 &pdma0 4>;
		dma-names = "tx", "rx";
		samsung,dma-phandle = <&sysreg_pdma_peri_sel>;
		samsung,dma-offset-tx = <5>;
		samsung,dma-offset-rx = <4>;
		samsung,dma-value = <1>;
		interrupts = <GIC_SPI INTREQ__USI02_USI IRQ_TYPE_LEVEL_HIGH>;
		samsung,usi-phandle = <&sysreg_peric2_2_usi>;
		samsung,usi-offset = <0x10>;
		samsung,usi-version = <3>;
		clocks = <&clock GATE_PERIC2_CMU_PERIC2_QCH>, <&clock DOUT_DIV_CLK_PERIC2_USI02>;
		clock-names = "gate_spi_clk", "ipclk_spi";
		pinctrl-names = "default";
		pinctrl-0 = <&spi2_bus>;
		reg = <0x0 0x11940000 0x1000>;
		status = "disabled";
	};

	/* USI03_USI */
	spi_3: spi@11960000 {
		compatible = "samsung,exynos-spi";
		samsung,spi-fifosize = <256>;
		swap-mode = <1>;
		#address-cells = <1>;
		#size-cells = <0>;
/*
		dma-mode;
*/
		dmas = <&pdma0 7 &pdma0 6>;
		dma-names = "tx", "rx";
		samsung,dma-phandle = <&sysreg_pdma_peri_sel>;
		samsung,dma-offset-tx = <7>;
		samsung,dma-offset-rx = <6>;
		samsung,dma-value = <1>;
		interrupts = <GIC_SPI INTREQ__USI03_USI IRQ_TYPE_LEVEL_HIGH>;
		samsung,usi-phandle = <&sysreg_peric2_2_usi>;
		samsung,usi-offset = <0x18>;
		samsung,usi-version = <3>;
		clocks = <&clock GATE_PERIC2_CMU_PERIC2_QCH>, <&clock DOUT_DIV_CLK_PERIC2_USI03>;
		clock-names = "gate_spi_clk", "ipclk_spi";
		pinctrl-names = "default";
		pinctrl-0 = <&spi3_bus>;
		reg = <0x0 0x11960000 0x1000>;
		status = "disabled";
	};

	/* USI04_USI */
	spi_4: spi@10900000 {
		compatible = "samsung,exynos-spi";
		samsung,spi-fifosize = <64>;
		swap-mode = <1>;
		#address-cells = <1>;
		#size-cells = <0>;
/*
		dma-mode;
*/
		dmas = <&pdma0 9 &pdma0 8>;
		dma-names = "tx", "rx";
		samsung,dma-phandle = <&sysreg_pdma_peri_sel>;
		samsung,dma-offset-tx = <9>;
		samsung,dma-offset-rx = <8>;
		samsung,dma-value = <1>;
		interrupts = <GIC_SPI INTREQ__USI04_USI IRQ_TYPE_LEVEL_HIGH>;
		samsung,usi-phandle = <&sysreg_peric0_1_usi>;
		samsung,usi-offset = <0x24>;
		samsung,usi-version = <3>;
		clocks = <&clock GATE_PERIC0_CMU_PERIC0_QCH>, <&clock DOUT_DIV_CLK_PERIC0_USI04>;
		clock-names = "gate_spi_clk", "ipclk_spi";
		pinctrl-names = "default";
		pinctrl-0 = <&spi4_bus>;
		reg = <0x0 0x10900000 0x1000>;
		status = "disabled";
	};

	/* USI05_USI_OIS */
	spi_5: spi@119D0000 {
		compatible = "samsung,exynos-spi";
		samsung,spi-fifosize = <64>;
		swap-mode = <1>;
		#address-cells = <1>;
		#size-cells = <0>;
/*
		dma-mode;
*/
		dmas = <&pdma0 11 &pdma0 10>;
		dma-names = "tx", "rx";
		samsung,dma-phandle = <&sysreg_pdma_peri_sel>;
		samsung,dma-offset-tx = <11>;
		samsung,dma-offset-rx = <10>;
		samsung,dma-value = <1>;
		interrupts = <GIC_SPI INTREQ__USI05_USI_OIS IRQ_TYPE_LEVEL_HIGH>;
		samsung,usi-phandle = <&sysreg_peric2_1_usi>;
		samsung,usi-offset = <0x17C>;
		samsung,usi-version = <3>;
		clocks = <&clock GATE_PERIC2_CMU_PERIC2_QCH>, <&clock DOUT_DIV_CLK_PERIC2_USI05>;
		clock-names = "gate_spi_clk", "ipclk_spi";
		pinctrl-names = "default";
		pinctrl-0 = <&spi5_bus>;
		reg = <0x0 0x119D0000 0x1000>;
		status = "disabled";
	};

	/* USI06_USI */
	spi_6: spi@119E0000 {
		compatible = "samsung,exynos-spi";
		samsung,spi-fifosize = <256>;
		swap-mode = <1>;
		#address-cells = <1>;
		#size-cells = <0>;
/*
		dma-mode;
*/
		dmas = <&pdma0 13 &pdma0 12>;
		dma-names = "tx", "rx";
		samsung,dma-phandle = <&sysreg_pdma_peri_sel>;
		samsung,dma-offset-tx = <13>;
		samsung,dma-offset-rx = <12>;
		samsung,dma-value = <1>;
		interrupts = <GIC_SPI INTREQ__USI06_USI_OIS IRQ_TYPE_LEVEL_HIGH>;
		samsung,usi-phandle = <&sysreg_peric2_1_usi>;
		samsung,usi-offset = <0x180>;
		samsung,usi-version = <3>;
		clocks = <&clock GATE_PERIC2_CMU_PERIC2_QCH>, <&clock DOUT_DIV_CLK_PERIC2_USI06>;
		clock-names = "gate_spi_clk", "ipclk_spi";
		pinctrl-names = "default";
		pinctrl-0 = <&spi6_bus>;
		reg = <0x0 0x119E0000 0x1000>;
		status = "disabled";
	};

	/* USI07_USI */
	spi_7: spi@11050000 {
		compatible = "samsung,exynos-spi";
		samsung,spi-fifosize = <64>;
		swap-mode = <1>;
		#address-cells = <1>;
		#size-cells = <0>;
/*
		dma-mode;
*/
		dmas = <&pdma0 15 &pdma0 14>;
		dma-names = "tx", "rx";
		samsung,dma-phandle = <&sysreg_pdma_peri_sel>;
		samsung,dma-offset-tx = <15>;
		samsung,dma-offset-rx = <14>;
		samsung,dma-value = <1>;
		interrupts = <GIC_SPI INTREQ__USI07_USI IRQ_TYPE_LEVEL_HIGH>;
		samsung,usi-phandle = <&sysreg_peric1_2_usi>;
		samsung,usi-offset = <0x30>;
		samsung,usi-version = <3>;
		clocks = <&clock GATE_PERIC1_CMU_PERIC1_QCH>, <&clock DOUT_DIV_CLK_PERIC1_USI07>;
		clock-names = "gate_spi_clk", "ipclk_spi";
		pinctrl-names = "default";
		pinctrl-0 = <&spi7_bus>;
		reg = <0x0 0x11050000 0x1000>;
		status = "disabled";
	};

	/* USI08_USI */
	spi_8: spi@11070000 {
		compatible = "samsung,exynos-spi";
		samsung,spi-fifosize = <64>;
		swap-mode = <1>;
		#address-cells = <1>;
		#size-cells = <0>;
/*
		dma-mode;
*/
		dmas = <&pdma0 17 &pdma0 16>;
		dma-names = "tx", "rx";
		samsung,dma-phandle = <&sysreg_pdma_peri_sel>;
		samsung,dma-offset-tx = <17>;
		samsung,dma-offset-rx = <16>;
		samsung,dma-value = <1>;
		interrupts = <GIC_SPI INTREQ__USI08_USI IRQ_TYPE_LEVEL_HIGH>;
		samsung,usi-phandle = <&sysreg_peric1_2_usi>;
		samsung,usi-offset = <0x38>;
		samsung,usi-version = <3>;
		clocks = <&clock GATE_PERIC1_CMU_PERIC1_QCH>, <&clock DOUT_DIV_CLK_PERIC1_USI08>;
		clock-names = "gate_spi_clk", "ipclk_spi";
		pinctrl-names = "default";
		pinctrl-0 = <&spi8_bus>;
		reg = <0x0 0x11070000 0x1000>;
		status = "disabled";
	};

	/* USI09_USI */
	spi_9: spi@11090000 {
		compatible = "samsung,exynos-spi";
		samsung,spi-fifosize = <64>;
		swap-mode = <1>;
		#address-cells = <1>;
		#size-cells = <0>;
/*
		dma-mode;
*/
		dmas = <&pdma0 19 &pdma0 18>;
		dma-names = "tx", "rx";
		samsung,dma-phandle = <&sysreg_pdma_peri_sel>;
		samsung,dma-offset-tx = <19>;
		samsung,dma-offset-rx = <18>;
		samsung,dma-value = <1>;
		interrupts = <GIC_SPI INTREQ__USI09_USI IRQ_TYPE_LEVEL_HIGH>;
		samsung,usi-phandle = <&sysreg_peric1_2_usi>;
		samsung,usi-offset = <0x40>;
		samsung,usi-version = <3>;
		clocks = <&clock GATE_PERIC1_CMU_PERIC1_QCH>, <&clock DOUT_DIV_CLK_PERIC1_USI09>;
		clock-names = "gate_spi_clk", "ipclk_spi";
		pinctrl-names = "default";
		pinctrl-0 = <&spi9_bus>;
		reg = <0x0 0x11090000 0x1000>;
		status = "disabled";
	};

	/* USI10_USI */
	spi_10: spi@110C0000 {
		compatible = "samsung,exynos-spi";
		samsung,spi-fifosize = <64>;
		swap-mode = <1>;
		#address-cells = <1>;
		#size-cells = <0>;
/*
		dma-mode;
*/
		dmas = <&pdma0 21 &pdma0 20>;
		dma-names = "tx", "rx";
		samsung,dma-phandle = <&sysreg_pdma_peri_sel>;
		samsung,dma-offset-tx = <21>;
		samsung,dma-offset-rx = <20>;
		samsung,dma-value = <1>;
		interrupts = <GIC_SPI INTREQ__USI10_USI IRQ_TYPE_LEVEL_HIGH>;
		samsung,usi-phandle = <&sysreg_peric1_1_usi>;
		samsung,usi-offset = <0x10>;
		samsung,usi-version = <3>;
		clocks = <&clock GATE_PERIC1_CMU_PERIC1_QCH>, <&clock DOUT_DIV_CLK_PERIC1_USI10>;
		clock-names = "gate_spi_clk", "ipclk_spi";
		pinctrl-names = "default";
		pinctrl-0 = <&spi10_bus>;
		reg = <0x0 0x110C0000 0x1000>;
		status = "disabled";
	};

	/* USI11_USI */
	spi_11: spi@119A0000 {
		compatible = "samsung,exynos-spi";
		samsung,spi-fifosize = <64>;
		swap-mode = <1>;
		#address-cells = <1>;
		#size-cells = <0>;
/*
		dma-mode;
*/
		dmas = <&pdma0 23 &pdma0 22>;
		dma-names = "tx", "rx";
		samsung,dma-phandle = <&sysreg_pdma_peri_sel>;
		samsung,dma-offset-tx = <23>;
		samsung,dma-offset-rx = <22>;
		samsung,dma-value = <1>;
		interrupts = <GIC_SPI INTREQ__USI11_USI IRQ_TYPE_LEVEL_HIGH>;
		samsung,usi-phandle = <&sysreg_peric2_1_usi>;
		samsung,usi-offset = <0x58>;
		samsung,usi-version = <3>;
		clocks = <&clock GATE_PERIC2_CMU_PERIC2_QCH>, <&clock DOUT_DIV_CLK_PERIC2_USI11>;
		clock-names = "gate_spi_clk", "ipclk_spi";
		pinctrl-names = "default";
		pinctrl-0 = <&spi11_bus>;
		reg = <0x0 0x119A0000 0x1000>;
		status = "disabled";
	};

	/* USI_CMGP00 */
	spi_12: spi@15100000 {
		compatible = "samsung,exynos-spi";
		samsung,spi-fifosize = <64>;
		swap-mode = <1>;
		#address-cells = <1>;
		#size-cells = <0>;
		interrupts = <GIC_SPI INTREQ__USI_CMGP0 IRQ_TYPE_LEVEL_HIGH>;
		samsung,usi-phandle = <&sysreg_cmgp_usi>;
		samsung,usi-offset = <0x00>;
		samsung,usi-version = <3>;
		clocks = <&clock GATE_USI_CMGP0_QCH>, <&clock DOUT_DIV_CLK_CMGP_USI0>;
		clock-names = "gate_spi_clk", "ipclk_spi";
		pinctrl-names = "default";
		pinctrl-0 = <&spi12_bus>;
		reg = <0x0 0x15100000 0x1000>;
		status = "disabled";
	};

	/* USI_CMGP01 */
	spi_13: spi@15120000 {
		compatible = "samsung,exynos-spi";
		samsung,spi-fifosize = <64>;
		swap-mode = <1>;
		#address-cells = <1>;
		#size-cells = <0>;
		interrupts = <GIC_SPI INTREQ__USI_CMGP1 IRQ_TYPE_LEVEL_HIGH>;
		samsung,usi-phandle = <&sysreg_cmgp_usi>;
		samsung,usi-offset = <0x10>;
		samsung,usi-version = <3>;
		clocks = <&clock GATE_USI_CMGP1_QCH>, <&clock DOUT_DIV_CLK_CMGP_USI1>;
		clock-names = "gate_spi_clk", "ipclk_spi";
		pinctrl-names = "default";
		pinctrl-0 = <&spi13_bus>;
		reg = <0x0 0x15120000 0x1000>;
		status = "disabled";
	};

	/* USI_CMGP02 */
	spi_14: spi@15140000 {
		compatible = "samsung,exynos-spi";
		samsung,spi-fifosize = <64>;
		swap-mode = <1>;
		#address-cells = <1>;
		#size-cells = <0>;
		interrupts = <GIC_SPI INTREQ__USI_CMGP2 IRQ_TYPE_LEVEL_HIGH>;
		samsung,usi-phandle = <&sysreg_cmgp_usi>;
		samsung,usi-offset = <0x20>;
		samsung,usi-version = <3>;
		clocks = <&clock GATE_USI_CMGP2_QCH>, <&clock DOUT_DIV_CLK_CMGP_USI2>;
		clock-names = "gate_spi_clk", "ipclk_spi";
		pinctrl-names = "default";
		pinctrl-0 = <&spi14_bus>;
		reg = <0x0 0x15140000 0x1000>;
		status = "disabled";
	};

	/* USI_CMGP03 */
/*
	spi_15: spi@15160000 {
		compatible = "samsung,exynos-spi";
		samsung,spi-fifosize = <64>;
		swap-mode = <1>;
		#address-cells = <1>;
		#size-cells = <0>;
		interrupts = <GIC_SPI INTREQ__USI_CMGP3 IRQ_TYPE_LEVEL_HIGH>;
		samsung,usi-phandle = <&sysreg_cmgp_usi>;
		samsung,usi-offset = <0x30>;
		samsung,usi-version = <3>;
		clocks = <&clock GATE_USI_CMGP3_QCH>, <&clock DOUT_DIV_CLK_CMGP_USI3>;
		clock-names = "gate_spi_clk", "ipclk_spi";
		pinctrl-names = "default";
		pinctrl-0 = <&spi15_bus>;
		reg = <0x0 0x15160000 0x1000>;
		status = "disabled";
	};
*/
	/* USI_CMGP04 */
	spi_16: spi@15180000 {
		compatible = "samsung,exynos-spi";
		samsung,spi-fifosize = <64>;
		swap-mode = <1>;
		#address-cells = <1>;
		#size-cells = <0>;
		interrupts = <GIC_SPI INTREQ__USI_CMGP4 IRQ_TYPE_LEVEL_HIGH>;
		samsung,usi-phandle = <&sysreg_cmgp_usi>;
		samsung,usi-offset = <0x40>;
		samsung,usi-version = <3>;
		clocks = <&clock GATE_USI_CMGP4_QCH>, <&clock DOUT_DIV_CLK_CMGP_USI4>;
		clock-names = "gate_spi_clk", "ipclk_spi";
		pinctrl-names = "default";
		pinctrl-0 = <&spi16_bus>;
		reg = <0x0 0x15180000 0x1000>;
		status = "disabled";
	};

	/* USI_CMGP05 */
	spi_17: spi@151A0000 {
		compatible = "samsung,exynos-spi";
		samsung,spi-fifosize = <64>;
		swap-mode = <1>;
		#address-cells = <1>;
		#size-cells = <0>;
		interrupts = <GIC_SPI INTREQ__USI_CMGP5 IRQ_TYPE_LEVEL_HIGH>;
		samsung,usi-phandle = <&sysreg_cmgp_usi>;
		samsung,usi-offset = <0x50>;
		samsung,usi-version = <3>;
		clocks = <&clock GATE_USI_CMGP5_QCH>, <&clock DOUT_DIV_CLK_CMGP_USI5>;
		clock-names = "gate_spi_clk", "ipclk_spi";
		pinctrl-names = "default";
		pinctrl-0 = <&spi17_bus>;
		reg = <0x0 0x151A0000 0x1000>;
		status = "disabled";
	};

	/* USI_CMGP06 */
	spi_18: spi@151C0000 {
		compatible = "samsung,exynos-spi";
		samsung,spi-fifosize = <64>;
		swap-mode = <1>;
		#address-cells = <1>;
		#size-cells = <0>;
		interrupts = <GIC_SPI INTREQ__USI_CMGP6 IRQ_TYPE_LEVEL_HIGH>;
		samsung,usi-phandle = <&sysreg_cmgp_usi>;
		samsung,usi-offset = <0x60>;
		samsung,usi-version = <3>;
		clocks = <&clock GATE_USI_CMGP6_QCH>, <&clock DOUT_DIV_CLK_CMGP_USI6>;
		clock-names = "gate_spi_clk", "ipclk_spi";
		pinctrl-names = "default";
		pinctrl-0 = <&spi18_bus>;
		reg = <0x0 0x151C0000 0x1000>;
		status = "disabled";
	};

	/* USI22_SPI_I2C */
	spi_19: spi@108A0000 {
		compatible = "samsung,exynos-spi";
		samsung,spi-fifosize = <16>;
		swap-mode = <1>;
		#address-cells = <1>;
		#size-cells = <0>;
		interrupts = <GIC_SPI INTREQ__USI22_SPI_I2C IRQ_TYPE_LEVEL_HIGH>;
		samsung,usi-phandle = <&sysreg_peric0_2_usi>;
		samsung,usi-offset = <0x44>;
		samsung,usi-version = <3>;
		clocks = <&clock GATE_PERIC0_CMU_PERIC0_QCH>, <&clock DOUT_DIV_CLK_PERIC0_USI22_SPI_I2C>;
		clock-names = "gate_spi_clk", "ipclk_spi";
		pinctrl-names = "default";
		pinctrl-0 = <&spi19_bus>;
		reg = <0x0 0x108A0000 0x1000>;
		status = "disabled";
	};

	/* USI_PERIC0_DBG_UART */
	serial_0: uart@10840000 {
		compatible = "samsung,exynos-uart";
		samsung,separate-uart-clk;
		reg = <0x0 0x10840000 0x100>;
		samsung,fifo-size = <256>;
		samsung,uart-fifosize = <256>;
		reg-io-width = <4>;
		interrupts = <GIC_SPI INTREQ__DBG_UART IRQ_TYPE_LEVEL_HIGH>;
		pinctrl-names = "default";
		pinctrl-0 = <&uart0_bus>;
		samsung,usi-serial-v2;
		clocks = <&clock GATE_PERIC0_CMU_PERIC0_QCH>, <&clock DOUT_DIV_CLK_PERIC0_DBG_UART>;
		clock-names = "gate_uart_clk0", "ipclk_uart0";
		samsung,dbg-uart-ch;
		samsung,dbg-uart-baud = <115200>;
		samsung,dbg-word-len = <8>;
		samsung,source-clock-rate = <200000000>;
		status = "disabled";
	};

	/* USI_PERIC1_BT_UART */
	serial_1: uart@11040000 {
		compatible = "samsung,exynos-uart";
		samsung,separate-uart-clk;
		reg = <0x0 0x11040000 0x100>;
		samsung,fifo-size = <256>;
		reg-io-width = <4>;
		interrupts = <GIC_SPI INTREQ__BT_UART IRQ_TYPE_LEVEL_HIGH>;
		pinctrl-names = "default", "rts", "tx_dat";
		pinctrl-0 = <&uart1_bus_single &uart1_bus_rxd_hiz>; /* or _bus_dual */
		pinctrl-1 = <&uart1_bus_rts &uart1_bus_tx_con>;
		pinctrl-2 = <&uart1_bus_tx_dat>;
		samsung,usi-serial-v2;
		clocks = <&clock GATE_PERIC1_CMU_PERIC1_QCH>, <&clock DOUT_DIV_CLK_PERIC1_UART_BT>;
		clock-names = "gate_uart_clk1", "ipclk_uart1";
		status = "okay";
	};

	/* USI_PERIC2_USI00_UART */
	serial_2: uart@11900000 {
		compatible = "samsung,exynos-uart";
		samsung,separate-uart-clk;
		reg = <0x0 0x11900000 0x100>;
		samsung,fifo-size = <64>;
		reg-io-width = <4>;
		interrupts = <GIC_SPI INTREQ__USI00_USI IRQ_TYPE_LEVEL_HIGH>;
		pinctrl-names = "default";
		pinctrl-0 = <&uart2_bus_single>; /* or _bus_dual */
		samsung,usi-serial-v2;
		clocks = <&clock GATE_PERIC2_CMU_PERIC2_QCH>, <&clock DOUT_DIV_CLK_PERIC2_USI00>;
		clock-names = "gate_uart_clk2", "ipclk_uart2";
		samsung,usi-phandle = <&sysreg_peric2_2_usi>;
		samsung,usi-offset = <0x00>;
		status = "disabled";
	};

	/* USI_PERIC2_USI01_UART */
	serial_3: uart@11920000 {
		compatible = "samsung,exynos-uart";
		samsung,separate-uart-clk;
		reg = <0x0 0x11920000 0x100>;
		samsung,fifo-size = <64>;
		reg-io-width = <4>;
		interrupts = <GIC_SPI INTREQ__USI01_USI IRQ_TYPE_LEVEL_HIGH>;
		pinctrl-names = "default";
		pinctrl-0 = <&uart3_bus_single>; /* or _bus_dual */
		samsung,usi-serial-v2;
		clocks = <&clock GATE_PERIC2_CMU_PERIC2_QCH>, <&clock DOUT_DIV_CLK_PERIC2_USI01>;
		clock-names = "gate_uart_clk3", "ipclk_uart3";
		samsung,usi-phandle = <&sysreg_peric2_2_usi>;
		samsung,usi-offset = <0x08>;
		status = "disabled";
	};

	/* USI_PERIC2_USI02_UART */
	serial_4: uart@11940000 {
		compatible = "samsung,exynos-uart";
		samsung,separate-uart-clk;
		reg = <0x0 0x11940000 0x100>;
		samsung,fifo-size = <256>;
		reg-io-width = <4>;
		interrupts = <GIC_SPI INTREQ__USI02_USI IRQ_TYPE_LEVEL_HIGH>;
		pinctrl-names = "default";
		pinctrl-0 = <&uart4_bus_single>; /* or _bus_dual */
		samsung,usi-serial-v2;
		clocks = <&clock GATE_PERIC2_CMU_PERIC2_QCH>, <&clock DOUT_DIV_CLK_PERIC2_USI02>;
		clock-names = "gate_uart_clk4", "ipclk_uart4";
		samsung,usi-phandle = <&sysreg_peric2_2_usi>;
		samsung,usi-offset = <0x10>;
		status = "disabled";
	};

	/* USI_PERIC2_USI03_UART */
	serial_5: uart@11960000 {
		compatible = "samsung,exynos-uart";
		samsung,separate-uart-clk;
		reg = <0x0 0x11960000 0x100>;
		samsung,fifo-size = <256>;
		reg-io-width = <4>;
		interrupts = <GIC_SPI INTREQ__USI03_USI IRQ_TYPE_LEVEL_HIGH>;
		pinctrl-names = "default";
		pinctrl-0 = <&uart5_bus_single>; /* or _bus_dual */
		samsung,usi-serial-v2;
		clocks = <&clock GATE_PERIC2_CMU_PERIC2_QCH>, <&clock DOUT_DIV_CLK_PERIC2_USI03>;
		clock-names = "gate_uart_clk5", "ipclk_uart5";
		samsung,usi-phandle = <&sysreg_peric2_2_usi>;
		samsung,usi-offset = <0x18>;
		status = "disabled";
	};

	/* USI_PERIC0_USI04_UART */
	serial_6: uart@10900000 {
		compatible = "samsung,exynos-uart";
		samsung,separate-uart-clk;
		reg = <0x0 0x10900000 0x100>;
		samsung,fifo-size = <64>;
		reg-io-width = <4>;
		interrupts = <GIC_SPI INTREQ__USI04_USI IRQ_TYPE_LEVEL_HIGH>;
		pinctrl-names = "default";
		pinctrl-0 = <&uart6_bus_single>; /* or _bus_dual */
		samsung,usi-serial-v2;
		clocks = <&clock GATE_PERIC0_CMU_PERIC0_QCH>, <&clock DOUT_DIV_CLK_PERIC0_USI04>;
		clock-names = "gate_uart_clk6", "ipclk_uart6";
		samsung,usi-phandle = <&sysreg_peric0_1_usi>;
		samsung,usi-offset = <0x24>;
		status = "disabled";
	};

	/* USI_PERIC2_USI05_OIS_UART */
	serial_7: uart@119D0000 {
		compatible = "samsung,exynos-uart";
		samsung,separate-uart-clk;
		reg = <0x0 0x119D0000 0x100>;
		samsung,fifo-size = <64>;
		reg-io-width = <4>;
		interrupts = <GIC_SPI INTREQ__USI05_USI_OIS IRQ_TYPE_LEVEL_HIGH>;
		pinctrl-names = "default";
		pinctrl-0 = <&uart7_bus_single>; /* or _bus_dual */
		samsung,usi-serial-v2;
		clocks = <&clock GATE_PERIC2_CMU_PERIC2_QCH>, <&clock DOUT_DIV_CLK_PERIC2_USI05>;
		clock-names = "gate_uart_clk7", "ipclk_uart7";
		samsung,usi-phandle = <&sysreg_peric2_1_usi>;
		samsung,usi-offset = <0x17C>;
		status = "disabled";
	};

	/* USI_PERIC2_USI06_UART */
	serial_8: uart@119E0000 {
		compatible = "samsung,exynos-uart";
		samsung,separate-uart-clk;
		reg = <0x0 0x119E0000 0x100>;
		samsung,fifo-size = <256>;
		reg-io-width = <4>;
		interrupts = <GIC_SPI INTREQ__USI06_USI_OIS IRQ_TYPE_LEVEL_HIGH>;
		pinctrl-names = "default";
		pinctrl-0 = <&uart8_bus_single>; /* or _bus_dual */
		samsung,usi-serial-v2;
		clocks = <&clock GATE_PERIC2_CMU_PERIC2_QCH>, <&clock DOUT_DIV_CLK_PERIC2_USI06>;
		clock-names = "gate_uart_clk8", "ipclk_uart8";
		samsung,usi-phandle = <&sysreg_peric2_1_usi>;
		samsung,usi-offset = <0x180>;
		status = "disabled";
	};

	/* USI_PERIC1_USI07_UART */
	serial_9: uart@11050000 {
		compatible = "samsung,exynos-uart";
		samsung,separate-uart-clk;
		reg = <0x0 0x11050000 0x100>;
		samsung,fifo-size = <64>;
		reg-io-width = <4>;
		interrupts = <GIC_SPI INTREQ__USI07_USI IRQ_TYPE_LEVEL_HIGH>;
		pinctrl-names = "default";
		pinctrl-0 = <&uart9_bus_single>; /* or _bus_dual */
		samsung,usi-serial-v2;
		clocks = <&clock GATE_PERIC1_CMU_PERIC1_QCH>, <&clock DOUT_DIV_CLK_PERIC1_USI07>;
		clock-names = "gate_uart_clk9", "ipclk_uart9";
		samsung,usi-phandle = <&sysreg_peric1_2_usi>;
		samsung,usi-offset = <0x30>;
		status = "disabled";
	};

	/* USI_PERIC1_USI08_UART */
	serial_10: uart@11070000 {
		compatible = "samsung,exynos-uart";
		samsung,separate-uart-clk;
		reg = <0x0 0x11070000 0x100>;
		samsung,fifo-size = <64>;
		reg-io-width = <4>;
		interrupts = <GIC_SPI INTREQ__USI08_USI IRQ_TYPE_LEVEL_HIGH>;
		pinctrl-names = "default";
		pinctrl-0 = <&uart10_bus_single>; /* or _bus_dual */
		samsung,usi-serial-v2;
		clocks = <&clock GATE_PERIC1_CMU_PERIC1_QCH>, <&clock DOUT_DIV_CLK_PERIC1_USI08>;
		clock-names = "gate_uart_clk10", "ipclk_uart10";
		samsung,usi-phandle = <&sysreg_peric1_2_usi>;
		samsung,usi-offset = <0x38>;
		status = "disabled";
	};

	/* USI_PERIC1_USI09_UART */
	serial_11: uart@11090000 {
		compatible = "samsung,exynos-uart";
		samsung,separate-uart-clk;
		reg = <0x0 0x11090000 0x100>;
		samsung,fifo-size = <64>;
		reg-io-width = <4>;
		interrupts = <GIC_SPI INTREQ__USI09_USI IRQ_TYPE_LEVEL_HIGH>;
		pinctrl-names = "default";
		pinctrl-0 = <&uart11_bus_single>; /* or _bus_dual */
		samsung,usi-serial-v2;
		clocks = <&clock GATE_PERIC1_CMU_PERIC1_QCH>, <&clock DOUT_DIV_CLK_PERIC1_USI09>;
		clock-names = "gate_uart_clk11", "ipclk_uart11";
		samsung,usi-phandle = <&sysreg_peric1_2_usi>;
		samsung,usi-offset = <0x40>;
		status = "disabled";
	};

	/* USI_PERIC1_USI10_UART */
	serial_12: uart@110C0000 {
		compatible = "samsung,exynos-uart";
		samsung,separate-uart-clk;
		reg = <0x0 0x110C0000 0x100>;
		samsung,fifo-size = <64>;
		reg-io-width = <4>;
		interrupts = <GIC_SPI INTREQ__USI10_USI IRQ_TYPE_LEVEL_HIGH>;
		pinctrl-names = "default";
		pinctrl-0 = <&uart12_bus_single>; /* or _bus_dual */
		samsung,usi-serial-v2;
		clocks = <&clock GATE_PERIC1_CMU_PERIC1_QCH>, <&clock DOUT_DIV_CLK_PERIC1_USI10>;
		clock-names = "gate_uart_clk12", "ipclk_uart12";
		samsung,usi-phandle = <&sysreg_peric1_1_usi>;
		samsung,usi-offset = <0x10>;
		status = "disabled";
	};

	/* USI_PERIC2_USI11_UART */
	serial_13: uart@119A0000 {
		compatible = "samsung,exynos-uart";
		samsung,separate-uart-clk;
		reg = <0x0 0x119A0000 0x100>;
		samsung,fifo-size = <64>;
		reg-io-width = <4>;
		interrupts = <GIC_SPI INTREQ__USI11_USI IRQ_TYPE_LEVEL_HIGH>;
		pinctrl-names = "default";
		pinctrl-0 = <&uart13_bus_single>; /* or _bus_dual */
		samsung,usi-serial-v2;
		clocks = <&clock GATE_PERIC2_CMU_PERIC2_QCH>, <&clock DOUT_DIV_CLK_PERIC2_USI11>;
		clock-names = "gate_uart_clk13", "ipclk_uart13";
		samsung,usi-phandle = <&sysreg_peric2_1_usi>;
		samsung,usi-offset = <0x58>;
		status = "disabled";
	};

	/* USI_CMGP00_UART */
	serial_14: uart@15100000 {
		compatible = "samsung,exynos-uart";
		samsung,separate-uart-clk;
		reg = <0x0 0x15100000 0x100>;
		samsung,fifo-size = <64>;
		reg-io-width = <4>;
		interrupts = <GIC_SPI INTREQ__USI_CMGP0 IRQ_TYPE_LEVEL_HIGH>;
		pinctrl-names = "default";
		pinctrl-0 = <&uart14_bus_single>; /* or _bus_dual */
		samsung,usi-serial-v2;
		clocks = <&clock GATE_USI_CMGP0_QCH>, <&clock DOUT_DIV_CLK_CMGP_USI0>;
		clock-names = "gate_uart_clk14", "ipclk_uart14";
		samsung,usi-phandle = <&sysreg_cmgp_usi>;
		samsung,usi-offset = <0x00>;
		status = "disabled";
	};

	/* USI_CMGP01_UART */
	serial_15: uart@15120000 {
		compatible = "samsung,exynos-uart";
		samsung,separate-uart-clk;
		reg = <0x0 0x15120000 0x100>;
		samsung,fifo-size = <64>;
		reg-io-width = <4>;
		interrupts = <GIC_SPI INTREQ__USI_CMGP1 IRQ_TYPE_LEVEL_HIGH>;
		pinctrl-names = "default";
		pinctrl-0 = <&uart15_bus_single>; /* or _bus_dual */
		samsung,usi-serial-v2;
		clocks = <&clock GATE_USI_CMGP1_QCH>, <&clock DOUT_DIV_CLK_CMGP_USI1>;
		clock-names = "gate_uart_clk15", "ipclk_uart15";
		samsung,usi-phandle = <&sysreg_cmgp_usi>;
		samsung,usi-offset = <0x10>;
		status = "disabled";
	};

	/* USI_CMGP02_UART */
	serial_16: uart@15140000 {
		compatible = "samsung,exynos-uart";
		samsung,separate-uart-clk;
		reg = <0x0 0x15140000 0x100>;
		samsung,fifo-size = <64>;
		reg-io-width = <4>;
		interrupts = <GIC_SPI INTREQ__USI_CMGP2 IRQ_TYPE_LEVEL_HIGH>;
		pinctrl-names = "default";
		pinctrl-0 = <&uart16_bus_single>; /* or _bus_dual */
		samsung,usi-serial-v2;
		clocks = <&clock GATE_USI_CMGP2_QCH>, <&clock DOUT_DIV_CLK_CMGP_USI2>;
		clock-names = "gate_uart_clk16", "ipclk_uart16";
		samsung,usi-phandle = <&sysreg_cmgp_usi>;
		samsung,usi-offset = <0x20>;
		status = "disabled";
	};

	/* USI_CMGP03_UART */
/*
	serial_17: uart@15160000 {
		compatible = "samsung,exynos-uart";
		samsung,separate-uart-clk;
		reg = <0x0 0x15160000 0x100>;
		samsung,fifo-size = <64>;
		reg-io-width = <4>;
		interrupts = <GIC_SPI INTREQ__USI_CMGP3 IRQ_TYPE_LEVEL_HIGH>;
		pinctrl-names = "default";
		pinctrl-0 = <&uart17_bus_single>; // _bus_single or _bus_dual
		samsung,usi-serial-v2;
		clocks = <&clock GATE_USI_CMGP3_QCH>, <&clock DOUT_DIV_CLK_CMGP_USI3>;
		clock-names = "gate_uart_clk17", "ipclk_uart17";
		samsung,usi-phandle = <&sysreg_cmgp_usi>;
		samsung,usi-offset = <0x30>;
		status = "disabled";
	};
*/
	/* USI_CMGP04_UART */
	serial_18: uart@15180000 {
		compatible = "samsung,exynos-uart";
		samsung,separate-uart-clk;
		reg = <0x0 0x15180000 0x100>;
		samsung,fifo-size = <64>;
		reg-io-width = <4>;
		interrupts = <GIC_SPI INTREQ__USI_CMGP4 IRQ_TYPE_LEVEL_HIGH>;
		pinctrl-names = "default";
		pinctrl-0 = <&uart18_bus_single>; /* or _bus_dual */
		samsung,usi-serial-v2;
		clocks = <&clock GATE_USI_CMGP4_QCH>, <&clock DOUT_DIV_CLK_CMGP_USI4>;
		clock-names = "gate_uart_clk18", "ipclk_uart18";
		samsung,usi-phandle = <&sysreg_cmgp_usi>;
		samsung,usi-offset = <0x40>;
		status = "disabled";
	};

	/* USI_CMGP05_UART */
	serial_19: uart@151A0000 {
		compatible = "samsung,exynos-uart";
		samsung,separate-uart-clk;
		reg = <0x0 0x151A0000 0x100>;
		samsung,fifo-size = <64>;
		reg-io-width = <4>;
		interrupts = <GIC_SPI INTREQ__USI_CMGP5 IRQ_TYPE_LEVEL_HIGH>;
		pinctrl-names = "default";
		pinctrl-0 = <&uart19_bus_single>; /* or _bus_dual */
		samsung,usi-serial-v2;
		clocks = <&clock GATE_USI_CMGP5_QCH>, <&clock DOUT_DIV_CLK_CMGP_USI5>;
		clock-names = "gate_uart_clk19", "ipclk_uart19";
		samsung,usi-phandle = <&sysreg_cmgp_usi>;
		samsung,usi-offset = <0x50>;
		status = "disabled";
	};

	/* USI_CMGP06_UART */
	serial_20: uart@151C0000 {
		compatible = "samsung,exynos-uart";
		samsung,separate-uart-clk;
		reg = <0x0 0x151C0000 0x100>;
		samsung,fifo-size = <64>;
		reg-io-width = <4>;
		interrupts = <GIC_SPI INTREQ__USI_CMGP6 IRQ_TYPE_LEVEL_HIGH>;
		pinctrl-names = "default";
		pinctrl-0 = <&uart20_bus_single>; /* or _bus_dual */
		samsung,usi-serial-v2;
		clocks = <&clock GATE_USI_CMGP6_QCH>, <&clock DOUT_DIV_CLK_CMGP_USI6>;
		clock-names = "gate_uart_clk20", "ipclk_uart20";
		samsung,usi-phandle = <&sysreg_cmgp_usi>;
		samsung,usi-offset = <0x60>;
		status = "disabled";
	};
};
